VERSION ""

NS_ :

BS_:

BU_: MCPB MCPA EVCU2 AGSM

BO_ 2564502513 DIAGNOSTIC_REQUEST_FUNC_OBD: 8 EVCU2
 SG_ N_PDU : 7|64@0+ (1,0) [0|0] "" MCPB,MCPA

BO_ 156 TELEMATIC_FD_1: 32 EVCU2
 SG_ GPS_UTC_Second : 151|16@0+ (0.01,0) [0|59.99] "s"  MCPB,MCPA
 SG_ GPS_UTC_Minute : 47|8@0+ (1,0) [0|59] "min"  MCPB,MCPA
 SG_ GPS_UTC_Hour : 55|8@0+ (1,0) [0|23] "h"  MCPB,MCPA
 SG_ GPS_Date_Year : 167|16@0+ (1,0) [0|65534] "Years"  MCPB,MCPA
 SG_ GPS_Date_Month : 71|8@0+ (1,0) [1|12] "Months"  MCPB,MCPA
 SG_ GPS_Date_Day : 63|8@0+ (1,0) [1|31] "Days"  MCPB,MCPA

BO_ 1829 IPC_FD_1: 32 EVCU2
 SG_ TotalOdometer : 75|20@0+ (1,0) [0|1048575] "km"  MCPB,MCPA

BO_ 1626 IMPACT_INFO: 32 EVCU2
 SG_ IMPACTConfirm : 81|1@0+ (1,0) [0|1] "-"  MCPB,MCPA
 SG_ IMPACTCommand : 80|1@0+ (1,0) [0|1] "-"  MCPB,MCPA

BO_ 2564554482 DIAGNOSTIC_REQUEST_FD_FUNCTIONAL: 64 EVCU2
 SG_ N_PDU : 7|64@0+ (1,0) [0|0] "" MCPB,MCPA

BO_ 1155 BRAKE_FD_5: 32 EVCU2
 SG_ ESCFailSts : 83|1@0+ (1,0) [0|1] "-"  MCPB
 SG_ ABSFailSts : 87|1@0+ (1,0) [0|1] "-"  MCPB

BO_ 609 BRAKE_FD_4: 32 EVCU2
 SG_ EPBSts : 115|4@0+ (1,0) [0|14] "-"  MCPB,MCPA

BO_ 1066 BCM_FD_9: 32 EVCU2
 SG_ ExternalTemperature : 0|9@0+ (0.5,-85) [-85|170] "°C"  MCPB,MCPA

BO_ 1153 BCM_FD_10: 32 EVCU2
 SG_ CmdIgnSts : 138|3@0+ (1,0) [0|7] "" MCPB,MCPA
 SG_ MessageCounter_BCM10 : 179|4@0+ (1,0) [0|15] "-"  MCPB
 SG_ CRC_BCM10 : 191|8@0+ (1,0) [0|255] "-"  MCPB

BO_ 1032 HYBRID_THERMAL_COMMAND: 32 EVCU2
 SG_ EOPB_OIL_TEMP : 151|8@0+ (1,-50) [-50|205] "°C"  MCPB
 SG_ EOPB_OIL_FlwRate : 167|8@0+ (0.1,0) [0|25.4] "LPM"  MCPB
 SG_ EOPA_OIL_TEMP : 143|8@0+ (1,-50) [-50|205] "°C"  MCPA
 SG_ EOPA_OIL_FlwRate : 159|8@0+ (0.1,0) [0|25.4] "LPM"  MCPA

BO_ 267 HYBRID_SYSTEM_EPT1: 32 EVCU2
 SG_ WU_Timer_Value : 23|16@0+ (1,0) [0|65535] "min"  MCPB,MCPA
 SG_ PerWakeUp_Diag : 33|10@0+ (1,0) [0|1023] "-"  MCPB,MCPA

BO_ 1033 HYBRID_POWERTRAIN5: 32 EVCU2
 SG_ MessageCounter_HYBRID_POWERTRAI : 179|4@0+ (1,0) [0|15] "-"  Vector__XXX
 SG_ CRC_HYBRID_POWERTRAIN5 : 191|8@0+ (1,0) [0|255] "-"  Vector__XXX

BO_ 276 HYBRID_POWERTRAIN1: 64 EVCU2
 SG_ MessageCounter_HYBRID_POWERTRAI : 435|4@0+ (1,0) [0|15] "-"  Vector__XXX
 SG_ CRC_HYBRID_POWERTRAIN1 : 447|8@0+ (1,0) [0|255] "-"  Vector__XXX

BO_ 258 BRAKE_FD_2: 64 EVCU2
 SG_ MessageCounter_BRAKE2 : 435|4@0+ (1,0) [0|15] "-"  MCPB,MCPA
 SG_ LongAccelerationFailSts_BSM : 69|1@0+ (1,0) [0|1] "-"  MCPB,MCPA
 SG_ LongAcceleration_BSM : 35|12@0+ (0.02,-40.96) [-40.96|40.92] "m/s^2"  MCPB,MCPA
 SG_ LatAccelerationFailSts_BSM : 68|1@0+ (1,0) [0|1] "-"  MCPB,MCPA
 SG_ LatAcceleration_BSM : 19|12@0+ (0.02,-40.96) [-40.96|40.92] "m/s^2"  MCPB,MCPA
 SG_ ESCActive : 84|1@0+ (1,0) [0|1] "-"  MCPB,MCPA
 SG_ CRC_BRAKE2 : 447|8@0+ (1,0) [0|255] "-"  MCPB,MCPA
 SG_ ABSActive : 83|1@0+ (1,0) [0|1] "-"  MCPB,MCPA

BO_ 476 AGSM_FD_2: 32 AGSM
 SG_ PRNDFailSts : 82|1@0+ (1,0) [0|1] "-"  EVCU2
 SG_ PRNDdisplayFailSts : 83|1@0+ (1,0) [0|1] "-"  EVCU2
 SG_ APCM_Stat : 107|2@0+ (1,0) [0|2] "-"  EVCU2
 SG_ ShiftLeverPositionReq : 95|4@0+ (1,0) [0|15] "-"  EVCU2,MCPB
 SG_ MessageCounter_AGSM2 : 179|4@0+ (1,0) [0|15] "-"  EVCU2
 SG_ CRC_AGSM2 : 191|8@0+ (1,0) [0|255] "-"  EVCU2

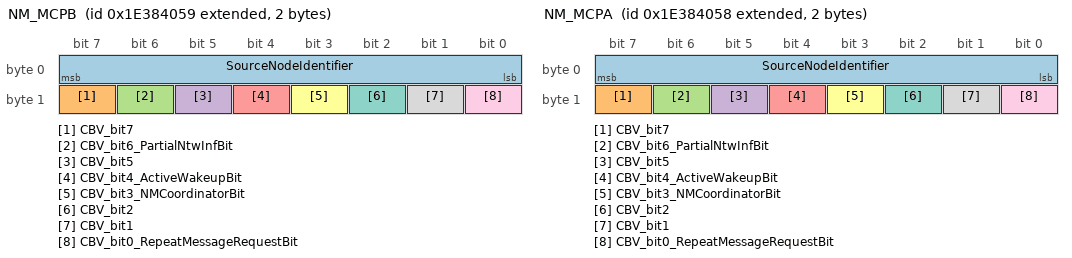
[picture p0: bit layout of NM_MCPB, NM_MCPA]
BO_ 2654486617 NM_MCPB: 2 MCPB
 SG_ SourceNodeIdentifier : 7|8@0+ (1,0) [0|255] "-"  EVCU2,MCPA,AGSM
 SG_ CBV_bit7 : 15|1@0+ (1,0) [0|1] "" EVCU2,MCPA,AGSM
 SG_ CBV_bit6_PartialNtwInfBit : 14|1@0+ (1,0) [0|1] "" EVCU2,MCPA,AGSM
 SG_ CBV_bit5 : 13|1@0+ (1,0) [0|1] "" EVCU2,MCPA,AGSM
 SG_ CBV_bit4_ActiveWakeupBit : 12|1@0+ (1,0) [0|1] "" EVCU2,MCPA,AGSM
 SG_ CBV_bit3_NMCoordinatorBit : 11|1@0+ (1,0) [0|1] "" EVCU2,MCPA,AGSM
 SG_ CBV_bit2 : 10|1@0+ (1,0) [0|1] "" EVCU2,MCPA,AGSM
 SG_ CBV_bit1 : 9|1@0+ (1,0) [0|1] "" EVCU2,MCPA,AGSM
 SG_ CBV_bit0_RepeatMessageRequestBit : 8|1@0+ (1,0) [0|1] "" EVCU2,MCPA,AGSM

BO_ 2654486616 NM_MCPA: 2 MCPA
 SG_ SourceNodeIdentifier : 7|8@0+ (1,0) [0|255] "-"  EVCU2,MCPB,AGSM
 SG_ CBV_bit7 : 15|1@0+ (1,0) [0|1] "" EVCU2,MCPB,AGSM
 SG_ CBV_bit6_PartialNtwInfBit : 14|1@0+ (1,0) [0|1] "" EVCU2,MCPB,AGSM
 SG_ CBV_bit5 : 13|1@0+ (1,0) [0|1] "" EVCU2,MCPB,AGSM
 SG_ CBV_bit4_ActiveWakeupBit : 12|1@0+ (1,0) [0|1] "" EVCU2,MCPB,AGSM
 SG_ CBV_bit3_NMCoordinatorBit : 11|1@0+ (1,0) [0|1] "" EVCU2,MCPB,AGSM
 SG_ CBV_bit2 : 10|1@0+ (1,0) [0|1] "" EVCU2,MCPB,AGSM
 SG_ CBV_bit1 : 9|1@0+ (1,0) [0|1] "" EVCU2,MCPB,AGSM
 SG_ CBV_bit0_RepeatMessageRequestBit : 8|1@0+ (1,0) [0|1] "" EVCU2,MCPB,AGSM

BO_ 496 PARK_DATA: 24 MCPB
 SG_ Plock_fdbk_sts : 7|3@0+ (1,0) [0|7] "" EVCU2
 SG_ MessageCounter_PARK_DATA : 115|4@0+ (1,0) [0|15] "" EVCU2
 SG_ CRC_PARK_DATA : 127|8@0+ (1,0) [0|255] "" EVCU2

BO_ 105 VDCM_PWT3: 64 EVCU2
 SG_ T7_Sensor_Temp : 330|11@0+ (0.1,-40) [-40|164.7] "°C"  MCPB,MCPA
 SG_ T7_CoolantTempVldty : 331|1@0+ (1,0) [0|1] "" MCPB,MCPA
 SG_ T4_Sensor_Temp : 378|11@0+ (0.1,-40) [-40|164.7] "°C"  MCPB,MCPA

BO_ 263 PT_SYSTEM_FD_1: 64 EVCU2
 SG_ GearEngagedForDisplay_PT : 12|5@0+ (1,0) [0|31] "" AGSM
 SG_ GearEngaged_PT : 132|4@0+ (1,0) [0|15] "" MCPB
 SG_ TransmissionFailSts_PT : 152|1@0+ (1,0) [0|1] "" AGSM
 SG_ ShiftLeverPosition_PT : 51|4@0+ (1,0) [0|15] "" AGSM
 SG_ MessageCounter_PT_SYSTEM_FD_1 : 435|4@0+ (1,0) [0|15] "-"  MCPB
 SG_ GearIndicationSts_PT : 153|1@0+ (1,0) [0|1] "" AGSM
 SG_ CRC_PT_SYSTEM_FD_1 : 447|8@0+ (1,0) [0|255] "-"  MCPB
 SG_ APCM_Rq_PT : 137|2@0+ (1,0) [0|3] "" AGSM

BO_ 216 PT_ENERGY_FD_1: 64 EVCU2
 SG_ BatteryVoltage_Raw_PT : 97|10@0+ (0.2,0) [0|204.60] "V"  MCPB,MCPA
 SG_ MC_PT_ENERGY_FD_1 : 435|4@0+ (1,0) [0|15] "" MCPB,MCPA
 SG_ CRC_PT_ENERGY_FD_1 : 447|8@0+ (1,0) [0|255] "" MCPB,MCPA

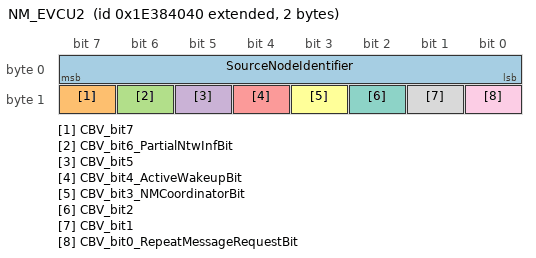
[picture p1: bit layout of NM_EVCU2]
BO_ 2654486592 NM_EVCU2: 2 EVCU2
 SG_ SourceNodeIdentifier : 7|8@0+ (1,0) [0|255] "-"  MCPB,MCPA,AGSM
 SG_ CBV_bit7 : 15|1@0+ (1,0) [0|1] "" MCPB,MCPA,AGSM
 SG_ CBV_bit6_PartialNtwInfBit : 14|1@0+ (1,0) [0|1] "" MCPB,MCPA,AGSM
 SG_ CBV_bit5 : 13|1@0+ (1,0) [0|1] "" MCPB,MCPA,AGSM
 SG_ CBV_bit4_ActiveWakeupBit : 12|1@0+ (1,0) [0|1] "" MCPB,MCPA,AGSM
 SG_ CBV_bit3_NMCoordinatorBit : 11|1@0+ (1,0) [0|1] "" MCPB,MCPA,AGSM
 SG_ CBV_bit2 : 10|1@0+ (1,0) [0|1] "" MCPB,MCPA,AGSM
 SG_ CBV_bit1 : 9|1@0+ (1,0) [0|1] "" MCPB,MCPA,AGSM
 SG_ CBV_bit0_RepeatMessageRequestBit : 8|1@0+ (1,0) [0|1] "" MCPB,MCPA,AGSM

BO_ 1811 REAL_TIME_CLOCK: 64 EVCU2
 SG_ Real_Time_Validity : 39|1@0+ (1,0) [0|1] "" MCPB,MCPA
 SG_ Real_Time_Clock : 7|32@0+ (1,0) [0|4294967295] "" MCPB,MCPA

BO_ 1065 MCPB_OBD_DTC: 32 MCPB
 SG_ MessageCounter_MCPB_OBD_DTC : 179|4@0+ (1,0) [0|15] ""  EVCU2
 SG_ MCPB_DTC_Stat2 : 26|3@0+ (1,0) [0|7] "" EVCU2
 SG_ MCPB_DTC_Stat1 : 18|3@0+ (1,0) [0|7] "" EVCU2
 SG_ MCPB_DTC_Idx2 : 31|5@0+ (1,0) [0|31] "" EVCU2
 SG_ MCPB_DTC_Idx1 : 23|5@0+ (1,0) [0|31] "" EVCU2
 SG_ MCPB_CalChar : 15|8@0+ (1,0) [0|255] "" EVCU2
 SG_ MCPB_Cal_ID_Idx : 7|6@0+ (1,0) [0|63] "" EVCU2
 SG_ CRC_MCPB_OBD_DTC : 191|8@0+ (1,0) [0|255] ""  EVCU2

BO_ 1057 MCPA_OBD_DTC: 32 MCPA
 SG_ MessageCounter_MCPA_OBD_DTC : 179|4@0+ (1,0) [0|15] ""  EVCU2
 SG_ MCPA_DTC_Stat2 : 26|3@0+ (1,0) [0|7] "" EVCU2
 SG_ MCPA_DTC_Stat1 : 18|3@0+ (1,0) [0|7] "" EVCU2
 SG_ MCPA_DTC_Idx2 : 31|5@0+ (1,0) [0|31] "" EVCU2
 SG_ MCPA_DTC_Idx1 : 23|5@0+ (1,0) [0|31] "" EVCU2
 SG_ MCPA_CalChar : 15|8@0+ (1,0) [0|255] "" EVCU2
 SG_ MCPA_Cal_ID_Idx : 7|6@0+ (1,0) [0|63] "" EVCU2
 SG_ CRC_MCPA_OBD_DTC : 191|8@0+ (1,0) [0|255] ""  EVCU2

BO_ 504 MCPB_STATUS: 32 MCPB
 SG_ MCPB_DerateReason_P : 7|4@0+ (1,0) [0|15] "-"  EVCU2
 SG_ MCPB_DC_Voltage_P : 1|10@0+ (1,0) [0|1022] "V"  EVCU2
 SG_ MCPB_DC_Volt_V_P : 3|1@0+ (1,0) [0|1] "" EVCU2
 SG_ MCPB_DC_Current_V_P : 2|1@0+ (1,0) [0|1] "" EVCU2
 SG_ MCPB_DC_Current_P : 38|15@0+ (0.1,-1638.4) [-1638.4|1638.3] "A"  EVCU2
 SG_ MCPB_CoolantTemp_P : 18|11@0+ (0.1,-40) [-40|164.7] "°C"  EVCU2
 SG_ MC_MCPB_STATUS : 179|4@0+ (1,0) [0|15] "-"  EVCU2
 SG_ CRC_MCPB_STATUS : 191|8@0+ (1,0) [0|255] "-"  EVCU2
 SG_ MCPB_Inverter_Temp_P : 71|8@0+ (1,-40) [-40|215] "°C"  EVCU2
 SG_ MCPB_PIM_DC_Side_Busbar_Temp_P : 79|8@0+ (1,-40) [-40|215] "°C"  EVCU2
 SG_ MCPB_Rotor_Temperature_P : 55|8@0+ (1,-40) [-40|215] "ºC"  EVCU2
 SG_ MCPB_Service_Lamp_Request_P : 19|1@0+ (1,0) [0|1] "" EVCU2
 SG_ CLrDiagInfo_MCPB_P : 39|1@0+ (1,0) [0|1] "" EVCU2
 SG_ MCPB_Control_Board_Temperature_P : 63|8@0+ (1,-40) [-40|215] "" EVCU2

BO_ 503 MCPA_STATUS: 32 MCPA
 SG_ MCPA_DerateReason_P : 7|4@0+ (1,0) [0|15] "" EVCU2
 SG_ MCPA_DC_Voltage_P : 1|10@0+ (1,0) [0|1023] "V"  EVCU2
 SG_ MCPA_DC_Volt_V_P : 3|1@0+ (1,0) [0|1] "" EVCU2
 SG_ MCPA_DC_Current_V_P : 2|1@0+ (1,0) [0|1] "" EVCU2
 SG_ MCPA_DC_Current_P : 38|15@0+ (0.1,-1638.4) [-1638.4|1638.3] "A"  EVCU2
 SG_ MCPA_CoolantTemp_P : 18|11@0+ (0.1,-40) [-40|164.7] "C"  EVCU2
 SG_ MC_MCPA_STATUS : 179|4@0+ (1,0) [0|15] "-"  EVCU2
 SG_ CRC_MCPA_STATUS : 191|8@0+ (1,0) [0|255] "-"  EVCU2
 SG_ MCPA_Inverter_Temp_P : 71|8@0+ (1,-40) [-40|215] "ºC"  EVCU2
 SG_ MCPA_PIM_DC_Side_Busbar_Temp_P : 79|8@0+ (1,-40) [-40|215] "ºC"  EVCU2
 SG_ MCPA_Rotor_Temperature_P : 55|8@0+ (1,-40) [-40|215] "ºC"  EVCU2
 SG_ MCPA_Service_Lamp_Request_P : 19|1@0+ (1,0) [0|1] "" EVCU2
 SG_ CLrDiagInfo_MCPA_P : 39|1@0+ (1,0) [0|1] "" EVCU2
 SG_ MCPA_Control_Board_Temperature_P : 63|8@0+ (1,-40) [-40|215] "ºC"  EVCU2

BO_ 297 INVTARGET_PROPULSION2: 48 EVCU2
 SG_ UDCMin_Unlim_MCPB_P : 111|16@0+ (0.01,0) [0|655.35] "V"  MCPB
 SG_ UDCMin_Unlim_MCPA_P : 23|16@0+ (0.01,0) [0|655.35] "V"  MCPA
 SG_ UDCMax_Unlim_MCPB_P : 143|16@0+ (0.01,0) [0|655.35] "V"  MCPB
 SG_ UDCMax_Unlim_MCPA_P : 39|16@0+ (0.01,0) [0|655.35] "V"  MCPA
 SG_ TqGrdtLim_MCPB_P : 79|16@0+ (0.1,0) [0|6553.5] "Nm/s"  MCPB
 SG_ TqGrdtLim_MCPA_P : 7|16@0+ (0.1,0) [0|6553.5] "Nm/s"  MCPA
 SG_ SpdGrdtLim_MCPB_P : 277|11@0+ (20,0) [0|40940] "rpm/s"  MCPB
 SG_ SpdGrdtLim_MCPA_P : 282|11@0+ (20,0) [0|40940] "rpm/s"  MCPA
 SG_ Pwr_Electr_Loop_FlwRate_MCPB_P : 63|8@0+ (0.1,0) [0|25.5] "LPM"  MCPB
 SG_ Pwr_Electr_Loop_FlwRate_MCPA_P : 55|8@0+ (0.1,0) [0|25.5] "LPM"  MCPA
 SG_ MC_INVTARGET_PROPULSION2 : 307|4@0+ (1,0) [0|15] "-"  MCPB,MCPA
 SG_ EVCU_MotorB_Speed : 191|16@0+ (1,-32768) [-32768|32767] "rpm"  MCPB
 SG_ EVCU_MotorA_Speed : 175|16@0+ (1,-32768) [-32768|32767] "rpm"  MCPA
 SG_ CRC_INVTARGET_PROPULSION2 : 319|8@0+ (1,0) [0|255] "-"  MCPB,MCPA

BO_ 296 INVTARGET_PROPULSION1: 48 EVCU2
 SG_ VehicleSpeedVSOSig_P : 55|13@0+ (0.0625,0) [0|511.875] "Km/h"  MCPB,MCPA
 SG_ TorqueCommand_MCPB_P : 157|14@0+ (0.125,-1023) [-1023|1024.875] "Nm"  MCPB
 SG_ TorqueCommand_MCPA_P : 139|14@0+ (0.125,-1023) [-1023|1024.875] "Nm"  MCPA
 SG_ TargetMotorRPM_MCPB_P : 23|16@0+ (0.5,-16384) [-16384|16383.5] "rpm"  MCPB
 SG_ TargetMotorRPM_MCPA_P : 7|16@0+ (0.5,-16384) [-16384|16383.5] "rpm"  MCPA
 SG_ ShiftLeverPosition_P : 273|4@0+ (1,0) [0|15] "" MCPB
 SG_ ParkCmd_PT_P : 259|2@0+ (1,0) [0|3] "" MCPB
 SG_ Mtr_6SO_Request_MCPB_P : 248|1@0+ (1,0) [0|1] "" MCPB
 SG_ Mtr_6SO_Request_MCPA_P : 249|1@0+ (1,0) [0|1] "" MCPA
 SG_ ModeCommand_MCPB_P : 227|4@0+ (1,0) [0|15] "" MCPB
 SG_ ModeCommand_MCPA_P : 231|4@0+ (1,0) [0|15] "" MCPA
 SG_ MC_INVTARGET_PROPULSION1 : 307|4@0+ (1,0) [0|15] "" MCPB,MCPA
 SG_ CRC_INVTARGET_PROPULSION1 : 319|8@0+ (1,0) [0|255] "-"  MCPB,MCPA
 SG_ CmdIgnSts_P : 58|3@0+ (1,0) [0|7] "" MCPB,MCPA
 SG_ BPCM_HV_TractionBusVoltage_P : 271|11@0+ (1,0) [0|2047] "V"  MCPB,MCPA
 SG_ BPCM_HV_Trac_Main_Contac_Sts_P : 276|3@0+ (1,0) [0|7] "" MCPB,MCPA
 SG_ AEMD_MinOffset_MCPB_P : 195|14@0+ (0.125,-1023) [-1023|1024.875] "Nm"  MCPB
 SG_ AEMD_MinOffset_MCPA_P : 119|14@0+ (0.125,-1023) [-1023|1024.875] "Nm"  MCPA
 SG_ AEMD_MaxOffset_MCPB_P : 213|14@0+ (0.125,-1023) [-1023|1024.875] "Nm"  MCPB
 SG_ AEMD_MaxOffset_MCPA_P : 121|14@0+ (0.125,-1023) [-1023|1024.875] "Nm"  MCPA
 SG_ AEMD_Cutoff_FreqLow_MCPB_P : 87|8@0+ (0.1,4.5) [4.5|30] "Hz"  MCPB
 SG_ AEMD_Cutoff_FreqLow_MCPA_P : 71|8@0+ (0.1,4.5) [4.5|30] "Hz"  MCPA
 SG_ AEMD_Cutoff_FreqHigh_MCPB_P : 95|8@0+ (0.1,0) [0|25.5] "Hz"  MCPB
 SG_ AEMD_Cutoff_FreqHigh_MCPA_P : 79|8@0+ (0.1,0) [0|25.5] "Hz"  MCPA
 SG_ AEMD_Sclr_Gn_MCPB_P : 242|9@0+ (0.02,0) [0|10.22] "rad/s/Nm"  MCPB
 SG_ AEMD_Sclr_Gn_MCPA_P : 235|9@0+ (0.02,0) [0|10.22] "rad/s/Nm"  MCPA

BO_ 124 GLIWA_MCPB_TX: 8 MCPB
 SG_ N_PDU : 7|64@0+ (1,0) [0|0] "" EVCU2

BO_ 127 GLIWA_MCPB_RX: 8 EVCU2
 SG_ N_PDU : 7|64@0+ (1,0) [0|0] "" MCPB

BO_ 123 GLIWA_MCPA_TX: 8 MCPA
 SG_ N_PDU : 7|64@0+ (1,0) [0|0] "" EVCU2

BO_ 126 GLIWA_MCPA_RX: 8 EVCU2
 SG_ N_PDU : 7|64@0+ (1,0) [0|0] "" MCPA

BO_ 294 MCPB_PROPULSION: 64 MCPB
 SG_ PlockFailSts_P : 179|3@0+ (1,0) [0|6] "" EVCU2
 SG_ Plock_PosSensor_P : 196|3@0+ (1,0) [0|6] "" EVCU2
 SG_ Plock_MotorPosSts_P : 188|3@0+ (1,0) [0|6] "" EVCU2
 SG_ Plock_fdbk_sts_P : 191|3@0+ (1,0) [0|7] "" EVCU2
 SG_ MPR_PosSensor_P : 199|3@0+ (1,0) [0|6] "" EVCU2
 SG_ MCPB_Torque_Achieved_V_P : 54|1@0+ (1,0) [0|1] "" EVCU2
 SG_ MCPB_Torque_Achieved_P : 21|14@0+ (0.125,-1023) [-1023|1024.875] "Nm"  EVCU2
 SG_ MCPB_TorqAchieved_AEMD_V_P : 71|1@0+ (1,0) [0|1] "" EVCU2
 SG_ MCPB_TorqAchieved_AEMD_P : 85|14@0+ (0.125,-1023) [-1023|1024.875] "Nm"  EVCU2
 SG_ MCPB_SPT_Stat_P : 39|2@0+ (1,0) [0|3] "" EVCU2
 SG_ MCPB_Spd_Lim_P : 135|16@0+ (1,-32767) [-32767|32678] "rpm"  EVCU2
 SG_ MCPB_RPM_V_P : 70|1@0+ (1,0) [0|1] "" EVCU2
 SG_ MCPB_RPM_P : 7|16@0+ (1,-32768) [-32768|32767] "rpm"  EVCU2
 SG_ MCPB_MtrMinCpbltyTrq_P : 117|14@0+ (0.125,-1023) [-1023|1024.875] "Nm"  EVCU2
 SG_ MCPB_MtrMaxCpbltyTrq_P : 101|14@0+ (0.125,-1023) [-1023|1024.875] "Nm"  EVCU2
 SG_ MCPB_MtrIndex_P : 44|5@0+ (1,0) [0|31] "" EVCU2
 SG_ MCPB_MinTorq_P : 69|14@0+ (0.125,-1023) [-1023|1024.875] "Nm"  EVCU2
 SG_ MCPB_MaxTorq_P : 53|14@0+ (0.125,-1023) [-1023|1024.875] "Nm"  EVCU2
 SG_ MCPB_Invrtr_State_P : 183|4@0+ (1,0) [0|15] "" EVCU2
 SG_ MCPB_InterlockSts_P : 103|2@0+ (1,0) [0|3] "" EVCU2
 SG_ MCPB_HV_CnctrOpn_Req_P : 119|1@0+ (1,0) [0|1] "" EVCU2
 SG_ MCPB_Dschrge_Status_P : 87|2@0+ (1,0) [0|3] "" EVCU2
 SG_ MCPB_DeratingFactor_P : 37|6@0+ (0.02,0) [0|1.26] "" EVCU2
 SG_ MCPB_CpbltySpdDivVolt_P : 167|16@0+ (1,0) [0|65535] "V"  EVCU2
 SG_ MCPB_AccelRawV_P : 55|1@0+ (1,0) [0|1] "" EVCU2
 SG_ MCPB_6SO_Status_P : 23|2@0+ (1,0) [0|3] "" EVCU2
 SG_ MCPB_3PS_Pos_P : 118|1@0+ (1,0) [0|1] "" EVCU2
 SG_ MCPB_AccelRaw_P : 151|16@0+ (1,-32768) [-32768|32767] "RPM/s"  EVCU2
 SG_ MC_MCPB_PROPULSION : 435|4@0+ (1,0) [0|15] "-"  EVCU2
 SG_ CRC_MCPB_PROPULSION : 447|8@0+ (1,0) [0|255] "-"  EVCU2
 SG_ MCPB_AC_Isolation_Status_P : 193|2@0+ (1,0) [0|3] "" EVCU2
 SG_ MCPB_Temp_P : 207|8@0+ (1,-40) [-40|215] "ºC"  EVCU2

BO_ 293 MCPA_PROPULSION: 64 MCPA
 SG_ MCPA_Torque_Achieved_V_P : 54|1@0+ (1,0) [0|1] "" EVCU2
 SG_ MCPA_Torque_Achieved_P : 21|14@0+ (0.125,-1023) [-1023|1024.875] "Nm"  EVCU2
 SG_ MCPA_TorqAchieved_AEMD_V_P : 71|1@0+ (1,0) [0|1] "" EVCU2
 SG_ MCPA_TorqAchieved_AEMD_P : 85|14@0+ (0.125,-1023) [-1023|1024.875] "Nm"  EVCU2
 SG_ MCPA_SPT_Stat_P : 39|2@0+ (1,0) [0|3] "" EVCU2
 SG_ MCPA_Spd_Lim_P : 135|16@0+ (1,-32767) [-32767|32768] "rpm"  EVCU2
 SG_ MCPA_RPM_V_P : 70|1@0+ (1,0) [0|1] "" EVCU2
 SG_ MCPA_RPM_P : 7|16@0+ (1,-32768) [-32768|32767] "rpm"  EVCU2
 SG_ MCPA_MtrMinCpbltyTrq_P : 117|14@0+ (0.125,-1023) [-1023|1024.875] "Nm"  EVCU2
 SG_ MCPA_MtrMaxCpbltyTrq_P : 101|14@0+ (0.125,-1023) [-1023|1024.875] "Nm"  EVCU2
 SG_ MCPA_MtrIndex_P : 44|5@0+ (1,0) [0|31] "" EVCU2
 SG_ MCPA_MinTorq_P : 69|14@0+ (0.125,-1023) [-1023|1024.875] "Nm"  EVCU2
 SG_ MCPA_MaxTorq_P : 53|14@0+ (0.125,-1023) [-1023|1024.875] "Nm"  EVCU2
 SG_ MCPA_Invrtr_State_P : 183|4@0+ (1,0) [0|15] "" EVCU2
 SG_ MCPA_InterlockSts_P : 103|2@0+ (1,0) [0|3] "" EVCU2
 SG_ MCPA_HV_CnctrOpn_Req_P : 119|1@0+ (1,0) [0|1] "" EVCU2
 SG_ MCPA_Dschrge_Status_P : 87|2@0+ (1,0) [0|3] "" EVCU2
 SG_ MCPA_DeratingFactor_P : 37|6@0+ (0.02,0) [0|1.26] "" EVCU2
 SG_ MCPA_CpbltySpdDivVolt_P : 167|16@0+ (1,0) [0|65535] "rpm"  EVCU2
 SG_ MCPA_AccelRawV_P : 55|1@0+ (1,0) [0|1] "" EVCU2
 SG_ MCPA_6SO_Status_P : 23|2@0+ (1,0) [0|3] "" EVCU2
 SG_ MCPA_3PS_Pos_P : 118|1@0+ (1,0) [0|1] "" EVCU2
 SG_ MCPA_AccelRaw_P : 151|16@0+ (1,-32768) [-32768|32767] "RPM/s"  EVCU2
 SG_ MC_MCPA_PROPULSION : 435|4@0+ (1,0) [0|15] "-"  EVCU2
 SG_ CRC_MCPA_PROPULSION : 447|8@0+ (1,0) [0|255] "-"  EVCU2
 SG_ MCPA_Temp_P : 207|8@0+ (1,-40) [-40|215] "°C"  EVCU2
 SG_ MCPA_AC_Isolation_Status_P : 199|2@0+ (1,0) [0|3] "" EVCU2

CM_ "Project_KM_ProjectStandard_FD-CAN16 [CS00155_FD]";
CM_ SG_ 2564502513 N_PDU "This signal is used for diagnostic purposes";
CM_ SG_ 156 GPS_UTC_Second "GPS UTC second";
CM_ SG_ 156 GPS_UTC_Minute "GPS UTC minute";
CM_ SG_ 156 GPS_UTC_Hour "GPS UTC hour";
CM_ SG_ 156 GPS_Date_Year "GPS date year";
CM_ SG_ 156 GPS_Date_Month "GPS date month";
CM_ SG_ 156 GPS_Date_Day "GPS date day";
CM_ SG_ 1829 TotalOdometer "Used to give information about the total odometer value in km.";
CM_ SG_ 1626 IMPACTConfirm "This signal is used to confirm that a crash happened";
CM_ SG_ 1626 IMPACTCommand "This signal is used to indicate that a crash happened";
CM_ SG_ 2564554482 N_PDU "This signal is used for diagnostic purposes";
CM_ SG_ 1155 ESCFailSts "0";
CM_ SG_ 1155 ABSFailSts "0";
CM_ SG_ 609 EPBSts "0";
CM_ SG_ 1153 MessageCounter_BCM10 "This signal is a counter used for safety checks strategies. This counter is incremented of 1 (one) unit at each frame transmission.";
CM_ SG_ 1153 CRC_BCM10 "CRC according to SAE J1850 standard at each frame transmission.";
CM_ SG_ 1153 CmdIgnSts "Used to give information about the key selector position";
CM_ SG_ 1032 EOPB_OIL_TEMP "EOPB Oil Temperature in EDM B";
CM_ SG_ 1032 EOPB_OIL_FlwRate "EOPB Oil Flow Rate through EDM B";
CM_ SG_ 1032 EOPA_OIL_TEMP "EOPA Oil Temperature in EDM A";
CM_ SG_ 1032 EOPA_OIL_FlwRate "EOPA Oil Flow Rate through EDM A";
CM_ SG_ 267 PerWakeUp_Diag "Periodic wakeup diagnostics";
CM_ SG_ 267 WU_Timer_Value "HCP wake-up timer value";
CM_ SG_ 1033 MessageCounter_HYBRID_POWERTRAI "This signal is a counter used for safety checks strategies. This counter is incremented of 1 (one) unit at each frame transmission.";
CM_ SG_ 1033 CRC_HYBRID_POWERTRAIN5 "CRC according to SAE J1850 standard at each frame transmission.";
CM_ SG_ 276 MessageCounter_HYBRID_POWERTRAI "This signal is a counter used for safety checks strategies. This counter is incremented of 1 (one) unit at each frame transmission.";
CM_ SG_ 276 CRC_HYBRID_POWERTRAIN1 "CRC according to SAE J1850 standard at each frame transmission.";
CM_ SG_ 258 MessageCounter_BRAKE2 "This signal is a counter used for safety checks strategies. This counter is incremented of 1 (one) unit at each frame transmission.";
CM_ SG_ 258 LongAccelerationFailSts_BSM "This signal indicates the status of Longitudinal acceleration signal";
CM_ SG_ 258 LongAcceleration_BSM "This signal indicates the Longitudinal Acceleration Value";
CM_ SG_ 258 LatAccelerationFailSts_BSM "This signal indicates the status of Lateral Acceleration Signal";
CM_ SG_ 258 LatAcceleration_BSM "This signal indicates the Lateral Acceleration Value";
CM_ SG_ 258 ESCActive "This signal is set to Active when the brake intervention by ESC is active.";
CM_ SG_ 258 CRC_BRAKE2 "CRC according to SAE J1850 standard at each frame transmission.";
CM_ SG_ 258 ABSActive "This signal is set to Active when the ABS functionality is active.";
CM_ SG_ 476 ShiftLeverPositionReq "This signal describes the shift lever position requested by the driver.";
CM_ SG_ 476 PRNDFailSts "-";
CM_ SG_ 476 PRNDdisplayFailSts "-";
CM_ SG_ 476 APCM_Stat "Auto position correction mode status";
CM_ SG_ 476 CRC_AGSM2 "CRC according to SAE J1850 standard at each frame transmission.";
CM_ SG_ 476 MessageCounter_AGSM2 "This signal is a counter used for safety checks strategies. This counter is incremented of 1 (one) unit at each frame transmission.";
CM_ SG_ 2654486617 SourceNodeIdentifier "Source Node Identifier";
CM_ SG_ 2654486617 CBV_bit6_PartialNtwInfBit "Partial Network Information Bit (PNI)";
CM_ SG_ 2654486617 CBV_bit4_ActiveWakeupBit "Active Wakeup Bit";
CM_ SG_ 2654486617 CBV_bit3_NMCoordinatorBit "NM Coordinator Sleep Bit";
CM_ SG_ 2654486617 CBV_bit0_RepeatMessageRequestBit "Repeat Message Request Bit";
CM_ SG_ 2654486616 SourceNodeIdentifier "Source Node Identifier";
CM_ SG_ 2654486616 CBV_bit6_PartialNtwInfBit "Partial Network Information Bit (PNI)";
CM_ SG_ 2654486616 CBV_bit4_ActiveWakeupBit "Active Wakeup Bit";
CM_ SG_ 2654486616 CBV_bit3_NMCoordinatorBit "NM Coordinator Sleep Bit";
CM_ SG_ 2654486616 CBV_bit0_RepeatMessageRequestBit "Repeat Message Request Bit";
CM_ SG_ 496 Plock_fdbk_sts "Park lock status";
CM_ SG_ 496 CRC_PARK_DATA "CRC according to SAE J1850 standard at each frame transmission.";
CM_ SG_ 496 MessageCounter_PARK_DATA "This signal is a counter used for safety checks strategies. This counter is incremented of 1 (one) unit at each frame transmission.";
CM_ SG_ 105 T7_Sensor_Temp "T7 Temperature sensor";
CM_ SG_ 105 T7_CoolantTempVldty "Inlet inverter temperature validity";
CM_ SG_ 105 T4_Sensor_Temp "T4 Temperature sensor";
CM_ SG_ 263 TransmissionFailSts_PT "Transmission Failure Status";
CM_ SG_ 263 ShiftLeverPosition_PT "Shift Lever Position";
CM_ SG_ 263 MessageCounter_PT_SYSTEM_FD_1 "This signal is a counter used for safety checks strategies. This counter is incremented of 1 (one) unit at each frame transmission.";
CM_ SG_ 263 GearIndicationSts_PT "Gear Indication Status";
CM_ SG_ 263 GearEngagedForDisplay_PT "Transmission Gear Engaged signal for the instrument cluster display";
CM_ SG_ 263 GearEngaged_PT "Current engaged gear";
CM_ SG_ 263 CRC_PT_SYSTEM_FD_1 "CRC according to SAE J1850 standard at each frame transmission.";
CM_ SG_ 263 APCM_Rq_PT "Auto position correction mode request";
CM_ SG_ 216 BatteryVoltage_Raw_PT "Battery Voltage value measured from the electrified powertrain control module pin";
CM_ SG_ 216 CRC_PT_ENERGY_FD_1 "CRC according to SAE J1850 standard at each frame transmission.";
CM_ SG_ 216 MC_PT_ENERGY_FD_1 "This signal is a counter used for safety checks strategies. This counter is incremented of 1 (one) unit at each frame transmission.";
CM_ SG_ 1811 Real_Time_Validity "EVCU Real Time Clock Validity";
CM_ SG_ 1811 Real_Time_Clock "EVCU Real Time Clock";
CM_ SG_ 1065 CRC_MCPB_OBD_DTC "CRC according to SAE J1850 standard at each frame transmission.";
CM_ SG_ 1065 MessageCounter_MCPB_OBD_DTC "This signal is a counter used for safety checks strategies. This counter is incremented of 1 (one) unit at each frame transmission.";
CM_ SG_ 1065 MCPB_DTC_Stat2 "MCPB diagnostic trouble code status 1";
CM_ SG_ 1065 MCPB_DTC_Stat1 "MCPB diagnostic trouble code status 1";
CM_ SG_ 1065 MCPB_DTC_Idx2 "MCPB diagnostic trouble code index 2";
CM_ SG_ 1065 MCPB_DTC_Idx1 "MCPB diagnostic trouble code index 1";
CM_ SG_ 1065 MCPB_CalChar "MCPB Calibration CVN";
CM_ SG_ 1065 MCPB_Cal_ID_Idx "MCPB Calibration ID Index";
CM_ SG_ 1057 MessageCounter_MCPA_OBD_DTC "This signal is a counter used for safety checks strategies. This counter is incremented of 1 (one) unit at each frame transmission.";
CM_ SG_ 1057 MCPA_DTC_Stat2 "MCPA diagnostic trouble code status 1";
CM_ SG_ 1057 MCPA_DTC_Stat1 "MCPA diagnostic trouble code status 1";
CM_ SG_ 1057 MCPA_DTC_Idx2 "MCPA diagnostic trouble code index 2";
CM_ SG_ 1057 MCPA_DTC_Idx1 "MCPA diagnostic trouble code index 1";
CM_ SG_ 1057 MCPA_CalChar "MCPA Calibration CVN";
CM_ SG_ 1057 MCPA_Cal_ID_Idx "MCPA Calibration ID Index";
CM_ SG_ 1057 CRC_MCPA_OBD_DTC "CRC according to SAE J1850 standard at each frame transmission.";
CM_ SG_ 504 MCPB_Rotor_Temperature_P "Rotor Temperature from Motor";
CM_ SG_ 504 MCPB_PIM_DC_Side_Busbar_Temp_P "MCPB busbar temperature in DC side";
CM_ SG_ 504 MCPB_Inverter_Temp_P "Motor Inverter Temperature";
CM_ SG_ 504 MCPB_DerateReason_P "Inverter Derating Reason.";
CM_ SG_ 504 MCPB_Service_Lamp_Request_P "The Service Light Request from the MCPB";
CM_ SG_ 504 MCPB_DC_Voltage_P "This signal indicates the Inverter Rear Right DC Voltage.";
CM_ SG_ 504 MCPB_DC_Volt_V_P "Achieved Torque value Validity, [1] = True";
CM_ SG_ 504 MCPB_DC_Current_V_P "Achieved Torque value Validity, [1] = True";
CM_ SG_ 504 MCPB_DC_Current_P "Motor B DC Current";
CM_ SG_ 504 MCPB_CoolantTemp_P "PIM Coolant Temperature";
CM_ SG_ 504 MCPB_Control_Board_Temperature_P "Motor Control Board temperature";
CM_ SG_ 504 MC_MCPB_STATUS "Message counter according to SAE J1850 standard that has to be calculated from bit 63 to bit 8 at each frame transmission.";
CM_ SG_ 504 CRC_MCPB_STATUS "CRC according to SAE J1850 standard that has to be calculated from bit 63 to bit 8 at each frame transmission.";
CM_ SG_ 504 CLrDiagInfo_MCPB_P "Legislative Diagnostic Clear information for MCPB";
CM_ SG_ 503 MCPA_Service_Lamp_Request_P "The Service Light Request from the MCPA";
CM_ SG_ 503 MCPA_Rotor_Temperature_P "Rotor Temperature from Motor";
CM_ SG_ 503 MCPA_PIM_DC_Side_Busbar_Temp_P "MCPA busbar temperature in DC side";
CM_ SG_ 503 MCPA_Inverter_Temp_P "Motor Inverter Temperature";
CM_ SG_ 503 MCPA_DerateReason_P "Inverter Derating Reason";
CM_ SG_ 503 MCPA_DC_Voltage_P "Inverter Front DC Voltage.";
CM_ SG_ 503 MCPA_DC_Volt_V_P "Motor A DC current validity, [1] = True";
CM_ SG_ 503 MCPA_DC_Current_V_P "Motor A DC current validity, [1] = True";
CM_ SG_ 503 MCPA_DC_Current_P "Motor A DC Current";
CM_ SG_ 503 MCPA_CoolantTemp_P "PIM Coolant Temperature";
CM_ SG_ 503 MCPA_Control_Board_Temperature_P "Motor Control Board temperature";
CM_ SG_ 503 MC_MCPA_STATUS "Message counter according to SAE J1850 standard that has to be calculated from bit 63 to bit 8 at each frame transmission.";
CM_ SG_ 503 CRC_MCPA_STATUS "CRC according to SAE J1850 standard that has to be calculated from bit 63 to bit 8 at each frame transmission.";
CM_ SG_ 503 CLrDiagInfo_MCPA_P "Legislative Diagnostic Clear information for MCPA";
CM_ SG_ 297 UDCMin_Unlim_MCPB_P "Minimum DC voltage limit before linear generator derating Consider Max or Min torque. Default 36V";
CM_ SG_ 297 UDCMin_Unlim_MCPA_P "Minimum DC voltage limit before linear generator derating Consider Max or Min torque. Default 36V";
CM_ SG_ 297 UDCMax_Unlim_MCPB_P "Maximum DC voltage limit before linear generator derating Consider Max or Min torque. Default 52V";
CM_ SG_ 297 UDCMax_Unlim_MCPA_P "Maximum DC voltage limit before linear generator derating Consider Max or Min torque. Default 52V";
CM_ SG_ 297 TqGrdtLim_MCPB_P "Positive or Negative Torque Gradient applied for Torque Control Mode and Speed Control Mode. Default 1000Nm/s";
CM_ SG_ 297 SpdGrdtLim_MCPB_P "Positive or negative (symetric) Speed Request Gradient applicable on both sign only for Speed Control Mode. Default 25,000 rpm/s";
CM_ SG_ 297 TqGrdtLim_MCPA_P "Positive or Negative Torque Gradient applied for Torque Control Mode and Speed Control Mode. Default 1000Nm/s";
CM_ SG_ 297 SpdGrdtLim_MCPA_P "Positive or negative (symetric) Speed Request Gradient applicable on both sign only for Speed Control Mode. Default 25,000 rpm/s";
CM_ SG_ 297 Pwr_Electr_Loop_FlwRate_MCPB_P "Inverter cooling liquid flow rate information";
CM_ SG_ 297 Pwr_Electr_Loop_FlwRate_MCPA_P "Inverter cooling liquid flow rate information";
CM_ SG_ 297 MC_INVTARGET_PROPULSION2 "Message counter according to SAE J1850 standard that has to be calculated from bit 63 to bit 8 at each frame transmission.";
CM_ SG_ 297 EVCU_MotorB_Speed "Motor B Speed Calculted by Supervisory Controller";
CM_ SG_ 297 EVCU_MotorA_Speed "Motor A Speed Calculted by Supervisory Controller";
CM_ SG_ 297 CRC_INVTARGET_PROPULSION2 "CRC according to SAE J1850 standard that has to be calculated from bit 63 to bit 8 at each frame transmission.";
CM_ SG_ 296 VehicleSpeedVSOSig_P "It is the average vehicle speed calculated.";
CM_ SG_ 296 TorqueCommand_MCPB_P "Torque command for MCPB";
CM_ SG_ 296 TorqueCommand_MCPA_P "Torque command for MCPA";
CM_ SG_ 296 TargetMotorRPM_MCPB_P "Target Motor RPM for MCPB";
CM_ SG_ 296 TargetMotorRPM_MCPA_P "Target Motor RPM for MCPA";
CM_ SG_ 296 ShiftLeverPosition_P "Shift Lever Position";
CM_ SG_ 296 ParkCmd_PT_P "Park Command for MCP.";
CM_ SG_ 296 Mtr_6SO_Request_MCPB_P "Six Switch Open Request  for MCPB (1=RequestActive; 0=RequestNotActive)";
CM_ SG_ 296 Mtr_6SO_Request_MCPA_P "Six Switch Open Request  for MCPA (1=RequestActive; 0=RequestNotActive)";
CM_ SG_ 296 ModeCommand_MCPB_P "Mode command for MCPB";
CM_ SG_ 296 ModeCommand_MCPA_P "Mode command for MCPA";
CM_ SG_ 296 CRC_INVTARGET_PROPULSION1 "CRC according to SAE J1850 standard that has to be calculated from bit 63 to bit 8 at each frame transmission.";
CM_ SG_ 296 CmdIgnSts_P "Used to give information about the key selector position";
CM_ SG_ 296 BPCM_HV_TractionBusVoltage_P "Battery link traction bus voltage.";
CM_ SG_ 296 BPCM_HV_Trac_Main_Contac_Sts_P "Traction main contactor physical relay status";
CM_ SG_ 296 AEMD_Sclr_Gn_MCPB_P "MCPB AEMD Scalar Gain";
CM_ SG_ 296 AEMD_Sclr_Gn_MCPA_P "MCPA AEMD Scalar Gain";
CM_ SG_ 296 AEMD_MinOffset_MCPB_P "MCPB AEMD Min Offset";
CM_ SG_ 296 AEMD_MinOffset_MCPA_P "MCPA AEMD Min Offset";
CM_ SG_ 296 AEMD_MaxOffset_MCPB_P "MCPB AEMD Max Offset";
CM_ SG_ 296 AEMD_MaxOffset_MCPA_P "MCPA AEMD Max Offset";
CM_ SG_ 296 AEMD_Cutoff_FreqLow_MCPB_P "AEMD cut-off Frequency Low for MCPB";
CM_ SG_ 296 AEMD_Cutoff_FreqLow_MCPA_P "AEMD cut-off Frequency Low for MCPA";
CM_ SG_ 296 AEMD_Cutoff_FreqHigh_MCPB_P "AEMD cut-off Frequency High for MCPB";
CM_ SG_ 296 AEMD_Cutoff_FreqHigh_MCPA_P "AEMD cut-off Frequency High for MCPA";
CM_ SG_ 294 PlockFailSts_P "Park Lock Fail Sts";
CM_ SG_ 294 Plock_PosSensor_P "Par lock physical position sensor feedback";
CM_ SG_ 294 Plock_MotorPosSts_P "Park lock motor position status";
CM_ SG_ 294 Plock_fdbk_sts_P "Park lock status";
CM_ SG_ 294 MPR_PosSensor_P "Manual Park Release sensor feedback";
CM_ SG_ 294 MCPB_Torque_Achieved_V_P "Achieved Torque value Validity, [1] = True";
CM_ SG_ 294 MCPB_Torque_Achieved_P "Motr B Torque Achieved";
CM_ SG_ 294 MCPB_TorqAchieved_AEMD_V_P "Motor Torque Achieved Validity";
CM_ SG_ 294 MCPB_TorqAchieved_AEMD_P "Motor Torque Achieved";
CM_ SG_ 294 MCPB_Temp_P "Motor Stator Temperature";
CM_ SG_ 294 MCPB_SPT_Stat_P "Inverter Isolation Status";
CM_ SG_ 294 MCPB_Spd_Lim_P "Limited motor speed during reduced performance from MCP B";
CM_ SG_ 294 MCPB_RPM_V_P "Motor B Speed Validity, [1] = True";
CM_ SG_ 294 MCPB_RPM_P "Motor B Speed Raw";
CM_ SG_ 294 MCPB_MtrMinCpbltyTrq_P "Motor B Min Capability Torque";
CM_ SG_ 294 MCPB_MtrMaxCpbltyTrq_P "Motor B Max Capability Torque";
CM_ SG_ 294 MCPB_MtrIndex_P "Motor B Capability Curve Array Index";
CM_ SG_ 294 MCPB_MinTorq_P "Motor B Minimum Torque";
CM_ SG_ 294 MCPB_MaxTorq_P "Motor B Maximum Torque";
CM_ SG_ 294 MCPB_Invrtr_State_P "Inverter State of Operation of Motor B";
CM_ SG_ 294 MCPB_InterlockSts_P "Rear right inverter interlock state";
CM_ SG_ 294 MCPB_HV_CnctrOpn_Req_P "HV Battery pack contactor request";
CM_ SG_ 294 MCPB_Dschrge_Status_P "The active discharge status of MCPB";
CM_ SG_ 294 MCPB_DeratingFactor_P "Motor B Derating Factor";
CM_ SG_ 294 MCPB_CpbltySpdDivVolt_P "Motor B Speed at Capability Curve";
CM_ SG_ 294 MCPB_AccelRawV_P "Motor B Acceleration Validity";
CM_ SG_ 294 MCPB_AccelRaw_P "Motor B Acceleration";
CM_ SG_ 294 MCPB_AC_Isolation_Status_P "Motor AC Isolation Status";
CM_ SG_ 294 MCPB_6SO_Status_P "Motor B 6SO Status";
CM_ SG_ 294 MCPB_3PS_Pos_P "3 phase motor short possible from MCP B; True = [1]";
CM_ SG_ 294 MC_MCPB_PROPULSION "Message counter according to SAE J1850 standard that has to be calculated from bit 63 to bit 8 at each frame transmission.";
CM_ SG_ 294 CRC_MCPB_PROPULSION "CRC according to SAE J1850 standard that has to be calculated from bit 63 to bit 8 at each frame transmission.";
CM_ SG_ 293 MCPA_Torque_Achieved_V_P "Achieved Torque value Validity, [1] = True";
CM_ SG_ 293 MCPA_Torque_Achieved_P "Motor A Torque Achieved";
CM_ SG_ 293 MCPA_TorqAchieved_AEMD_V_P "Motor Torque Achieved Validity";
CM_ SG_ 293 MCPA_TorqAchieved_AEMD_P "Motor Torque Achieved without AEMD";
CM_ SG_ 293 MCPA_Temp_P "Motor Stator Temperature";
CM_ SG_ 293 MCPA_SPT_Stat_P "Inverter Isolation Status";
CM_ SG_ 293 MCPA_Spd_Lim_P "Limited motor speed during reduced performance from MCPA";
CM_ SG_ 293 MCPA_RPM_V_P "Motor A Speed Validity, [1] = True";
CM_ SG_ 293 MCPA_RPM_P "Motor A Speed Raw";
CM_ SG_ 293 MCPA_MtrMinCpbltyTrq_P "Motor A Min Capability Torque";
CM_ SG_ 293 MCPA_MtrMaxCpbltyTrq_P "Motor A Max Capability Torque";
CM_ SG_ 293 MCPA_MtrIndex_P "Motor A Capability Curve Array Index";
CM_ SG_ 293 MCPA_MinTorq_P "Motor A Minimum Torque";
CM_ SG_ 293 MCPA_MaxTorq_P "Motor A Maximum Torque";
CM_ SG_ 293 MCPA_Invrtr_State_P "Inverter State of Operation of Motor A";
CM_ SG_ 293 MCPA_InterlockSts_P "Front inverter interlock state";
CM_ SG_ 293 MCPA_HV_CnctrOpn_Req_P "HV Battery pack contactor request";
CM_ SG_ 293 MCPA_Dschrge_Status_P "The active discharge status of MCPA";
CM_ SG_ 293 MCPA_DeratingFactor_P "Motor A Derating Factor";
CM_ SG_ 293 MCPA_CpbltySpdDivVolt_P "Motor A Speed at Capability Curve";
CM_ SG_ 293 MCPA_AccelRawV_P "Motor A Acceleration Validity";
CM_ SG_ 293 MCPA_AccelRaw_P "Motor A Acceleration";
CM_ SG_ 293 MCPA_AC_Isolation_Status_P "Motor AC Isolation Status";
CM_ SG_ 293 MCPA_6SO_Status_P "Motor A 6SO Status";
CM_ SG_ 293 MCPA_3PS_Pos_P "3 phase motor short possible from MCP B; True = [1]";
CM_ SG_ 293 MC_MCPA_PROPULSION "Message counter according to SAE J1850 standard that has to be calculated from bit 63 to bit 8 at each frame transmission.";
CM_ SG_ 293 CRC_MCPA_PROPULSION "CRC according to SAE J1850 standard that has to be calculated from bit 63 to bit 8 at each frame transmission.";
BA_DEF_ BU_ "NwmNodeType" ENUM "+15_NotWakeable","+30_Wakeable","+30_NotWakeable","kMaster","kSlave15","kSlave30","none";
BA_DEF_ BU_ "NmNodeType" ENUM "+15_NotWakeable","+30_Wakeable","+30_NotWakeable","kMaster","kSlave15","kSlave30","none";
BA_DEF_ BU_ "NmAsrCanMsgReducedTime" INT 1 65535;
BA_DEF_ BU_ "NmAsrNodeIdentifier" HEX 0 255;
BA_DEF_ BU_ "NmAsrNode" ENUM "No","Yes";
BA_DEF_ BU_ "NmNode" ENUM "No","Yes";
BA_DEF_ BU_ "NmStationAddress" HEX 0 255;
BA_DEF_ BU_ "Description" STRING ;
BA_DEF_ "VersionYear" INT 0 99;
BA_DEF_ "VersionWeek" INT 0 53;
BA_DEF_ "Version" HEX 0 255;
BA_DEF_ "NmAsrCanMsgCycleTime" INT 1 65535;
BA_DEF_ "NmAsrBaseAddress" HEX 235487232 2147483647;
BA_DEF_ "NmAsrMessageCount" INT 1 256;
BA_DEF_ "NmAsrRepeatMessageTime" INT 1 65535;
BA_DEF_ "NmAsrWaitBusSleepTime" INT 1 65535;
BA_DEF_ "NmAsrTimeoutTime" INT 1 65535;
BA_DEF_ "DBName" STRING ;
BA_DEF_ "Baudrate" INT 0 1000000;
BA_DEF_ "BusType" STRING ;
BA_DEF_ "NmType" STRING ;
BA_DEF_ "Manufacturer" STRING ;
BA_DEF_ BO_ "CANFD_BRS" ENUM "0","1";
BA_DEF_ BO_ "VFrameFormat" ENUM "StandardCAN","ExtendedCAN","reserved","reserved","reserved","reserved","reserved","reserved","reserved","reserved","reserved","reserved","reserved","reserved","StandardCAN_FD","ExtendedCAN_FD";
BA_DEF_ BO_ "DiagConnection" HEX 0 65535;
BA_DEF_ BO_ "DiagState" ENUM "No","Yes";
BA_DEF_ BO_ "NmAsrMessage" ENUM "No","Yes";
BA_DEF_ BO_ "GenMsgDelayTime" INT 0 65535;
BA_DEF_ BO_ "GenMsgCycleTime" INT 0 65535;
BA_DEF_ BO_ "GenMsgCycleTimeFast" INT 0 65535;
BA_DEF_ BO_ "GenMsgStartDelayTime" INT 0 65535;
BA_DEF_ BO_ "GenMsgILSupport" ENUM "No","Yes";
BA_DEF_ BO_ "GenMsgNrOfRepetition" INT 0 255;
BA_DEF_ BO_ "GenMsgSendType" ENUM "Cyclic","NotUsed","NotUsed","NotUsed","NotUsed","NotUsed","NotUsed","NotUsed","NoMsgSendType";
BA_DEF_ BO_ "NmMessage" ENUM "No","Yes";
BA_DEF_ BO_ "DiagResponse" ENUM "No","Yes";
BA_DEF_ BO_ "Type" ENUM "P","C","PE","COC","PE_Cntrl","E","E_Cntrl","OC","S","BAF","DC","EM","MM","ISO-TP","-";
BA_DEF_ BO_ "DiagRequest" ENUM "No","Yes";
BA_DEF_ SG_ "GenSigTimeoutTime_MCPB" INT 0 65535;
BA_DEF_ SG_ "GenSigTimeoutTime_MCPA" INT 0 65535;
BA_DEF_ SG_ "GenSigTimeoutTime_EVCU2" INT 0 65535;
BA_DEF_ SG_ "GenSigTimeoutTime_AGSM" INT 0 65535;
BA_DEF_ SG_ "SystemSignalLongSymbol" STRING ;
BA_DEF_ SG_ "GenSigSendType" ENUM "NotUsed","OnWrite","OnWriteWithRepetition","OnChange","OnChangeWithRepetition","IfActive","IfActiveWithRepetition","NoSigSendType";
BA_DEF_ SG_ "GenSigInactiveValue" INT 0 2147483647;
BA_DEF_ SG_ "GenSigStartValue" INT 0 2147483647;
BA_DEF_DEF_ "NwmNodeType" "none";
BA_DEF_DEF_ "NmNodeType" "none";
BA_DEF_DEF_ "NmAsrCanMsgReducedTime" 100;
BA_DEF_DEF_ "NmAsrNodeIdentifier" 0;
BA_DEF_DEF_ "NmAsrNode" "Yes";
BA_DEF_DEF_ "NmNode" "Yes";
BA_DEF_DEF_ "NmStationAddress" 0;
BA_DEF_DEF_ "Description" "";
BA_DEF_DEF_ "VersionYear" 23;
BA_DEF_DEF_ "VersionWeek" 46;
BA_DEF_DEF_ "Version" 160;
BA_DEF_DEF_ "NmAsrCanMsgCycleTime" 200;
BA_DEF_DEF_ "NmAsrBaseAddress" 506724352;
BA_DEF_DEF_ "NmAsrMessageCount" 256;
BA_DEF_DEF_ "NmAsrRepeatMessageTime" 800;
BA_DEF_DEF_ "NmAsrWaitBusSleepTime" 750;
BA_DEF_DEF_ "NmAsrTimeoutTime" 1000;
BA_DEF_DEF_ "DBName" "CAN";
BA_DEF_DEF_ "Baudrate" 500000;
BA_DEF_DEF_ "BusType" "CAN";
BA_DEF_DEF_ "NmType" "";
BA_DEF_DEF_ "Manufacturer" "Fiat";
BA_DEF_DEF_ "CANFD_BRS" "0";
BA_DEF_DEF_ "VFrameFormat" "StandardCAN_FD";
BA_DEF_DEF_ "DiagConnection" 0;
BA_DEF_DEF_ "DiagState" "No";
BA_DEF_DEF_ "NmAsrMessage" "No";
BA_DEF_DEF_ "GenMsgDelayTime" 0;
BA_DEF_DEF_ "GenMsgCycleTime" 0;
BA_DEF_DEF_ "GenMsgCycleTimeFast" 0;
BA_DEF_DEF_ "GenMsgStartDelayTime" 0;
BA_DEF_DEF_ "GenMsgILSupport" "No";
BA_DEF_DEF_ "GenMsgNrOfRepetition" 0;
BA_DEF_DEF_ "GenMsgSendType" "NoMsgSendType";
BA_DEF_DEF_ "NmMessage" "No";
BA_DEF_DEF_ "DiagResponse" "No";
BA_DEF_DEF_ "Type" "-";
BA_DEF_DEF_ "DiagRequest" "No";
BA_DEF_DEF_ "GenSigTimeoutTime_MCPB" 2500;
BA_DEF_DEF_ "GenSigTimeoutTime_MCPA" 2500;
BA_DEF_DEF_ "GenSigTimeoutTime_EVCU2" 2500;
BA_DEF_DEF_ "GenSigTimeoutTime_AGSM" 2500;
BA_DEF_DEF_ "SystemSignalLongSymbol" "";
BA_DEF_DEF_ "GenSigSendType" "NoSigSendType";
BA_DEF_DEF_ "GenSigInactiveValue" 0;
BA_DEF_DEF_ "GenSigStartValue" 0;
BA_ "NmAsrCanMsgCycleTime" 1000;
BA_ "NmAsrBaseAddress" 507002880;
BA_ "NmAsrRepeatMessageTime" 5000;
BA_ "NmAsrWaitBusSleepTime" 1000;
BA_ "NmAsrTimeoutTime" 8000;
BA_ "DBName" "FDCAN16";
BA_ "BusType" "CAN FD";
BA_ "NmType" "NmAsr";
BA_ "NwmNodeType" BU_ MCPB 1;
BA_ "NmNodeType" BU_ MCPB 1;
BA_ "NmAsrCanMsgReducedTime" BU_ MCPB 650;
BA_ "NmAsrNodeIdentifier" BU_ MCPB 89;
BA_ "NmStationAddress" BU_ MCPB 89;
BA_ "Description" BU_ MCPB "Motor Control Processor B";
BA_ "NwmNodeType" BU_ MCPA 1;
BA_ "NmNodeType" BU_ MCPA 1;
BA_ "NmAsrCanMsgReducedTime" BU_ MCPA 625;
BA_ "NmAsrNodeIdentifier" BU_ MCPA 88;
BA_ "NmStationAddress" BU_ MCPA 88;
BA_ "Description" BU_ MCPA "Motor Control Processor A";
BA_ "NwmNodeType" BU_ EVCU2 1;
BA_ "NmNodeType" BU_ EVCU2 1;
BA_ "NmAsrCanMsgReducedTime" BU_ EVCU2 950;
BA_ "NmAsrNodeIdentifier" BU_ EVCU2 64;
BA_ "NmStationAddress" BU_ EVCU2 64;
BA_ "Description" BU_ EVCU2 "Electric Vehicle Control Unit 2";
BA_ "NwmNodeType" BU_ AGSM 0;
BA_ "NmNodeType" BU_ AGSM 0;
BA_ "NmAsrNodeIdentifier" BU_ AGSM 22;
BA_ "NmAsrNode" BU_ AGSM 0;
BA_ "NmNode" BU_ AGSM 0;
BA_ "NmStationAddress" BU_ AGSM 22;
BA_ "Description" BU_ AGSM "Automatic Gearbox Shifter Module";
BA_ "VFrameFormat" BO_ 2564502513 1;
BA_ "DiagConnection" BO_ 2564502513 61747;
BA_ "DiagState" BO_ 2564502513 1;
BA_ "Type" BO_ 2564502513 8;
BA_ "CANFD_BRS" BO_ 156 1;
BA_ "GenMsgILSupport" BO_ 156 1;
BA_ "Type" BO_ 156 8;
BA_ "CANFD_BRS" BO_ 1829 1;
BA_ "GenMsgCycleTime" BO_ 1829 1000;
BA_ "GenMsgILSupport" BO_ 1829 1;
BA_ "GenMsgSendType" BO_ 1829 0;
BA_ "Type" BO_ 1829 1;
BA_ "CANFD_BRS" BO_ 1626 1;
BA_ "GenMsgCycleTime" BO_ 1626 500;
BA_ "GenMsgCycleTimeFast" BO_ 1626 10;
BA_ "GenMsgILSupport" BO_ 1626 1;
BA_ "GenMsgSendType" BO_ 1626 0;
BA_ "Type" BO_ 1626 10;
BA_ "CANFD_BRS" BO_ 2564554482 1;
BA_ "VFrameFormat" BO_ 2564554482 15;
BA_ "DiagConnection" BO_ 2564554482 62206;
BA_ "DiagState" BO_ 2564554482 1;
BA_ "Type" BO_ 2564554482 8;
BA_ "CANFD_BRS" BO_ 1155 1;
BA_ "GenMsgDelayTime" BO_ 1155 20;
BA_ "GenMsgCycleTime" BO_ 1155 500;
BA_ "GenMsgCycleTimeFast" BO_ 1155 20;
BA_ "GenMsgILSupport" BO_ 1155 1;
BA_ "GenMsgNrOfRepetition" BO_ 1155 2;
BA_ "GenMsgSendType" BO_ 1155 0;
BA_ "Type" BO_ 1155 3;
BA_ "CANFD_BRS" BO_ 609 1;
BA_ "GenMsgCycleTime" BO_ 609 100;
BA_ "GenMsgCycleTimeFast" BO_ 609 20;
BA_ "GenMsgStartDelayTime" BO_ 609 50;
BA_ "GenMsgILSupport" BO_ 609 1;
BA_ "GenMsgNrOfRepetition" BO_ 609 2;
BA_ "GenMsgSendType" BO_ 609 0;
BA_ "Type" BO_ 609 3;
BA_ "CANFD_BRS" BO_ 1066 1;
BA_ "GenMsgDelayTime" BO_ 1066 20;
BA_ "GenMsgCycleTime" BO_ 1066 250;
BA_ "GenMsgCycleTimeFast" BO_ 1066 20;
BA_ "GenMsgILSupport" BO_ 1066 1;
BA_ "GenMsgNrOfRepetition" BO_ 1066 2;
BA_ "GenMsgSendType" BO_ 1066 0;
BA_ "Type" BO_ 1066 3;
BA_ "CANFD_BRS" BO_ 1153 1;
BA_ "GenMsgDelayTime" BO_ 1153 20;
BA_ "GenMsgCycleTime" BO_ 1153 500;
BA_ "GenMsgCycleTimeFast" BO_ 1153 20;
BA_ "GenMsgILSupport" BO_ 1153 1;
BA_ "GenMsgNrOfRepetition" BO_ 1153 2;
BA_ "GenMsgSendType" BO_ 1153 0;
BA_ "Type" BO_ 1153 3;
BA_ "CANFD_BRS" BO_ 1032 1;
BA_ "GenMsgCycleTime" BO_ 1032 100;
BA_ "GenMsgILSupport" BO_ 1032 1;
BA_ "GenMsgSendType" BO_ 1032 0;
BA_ "Type" BO_ 1032 1;
BA_ "CANFD_BRS" BO_ 267 1;
BA_ "GenMsgCycleTime" BO_ 267 10;
BA_ "GenMsgILSupport" BO_ 267 1;
BA_ "GenMsgSendType" BO_ 267 0;
BA_ "Type" BO_ 267 1;
BA_ "CANFD_BRS" BO_ 1033 1;
BA_ "GenMsgCycleTime" BO_ 1033 100;
BA_ "GenMsgILSupport" BO_ 1033 1;
BA_ "GenMsgSendType" BO_ 1033 0;
BA_ "Type" BO_ 1033 1;
BA_ "CANFD_BRS" BO_ 276 1;
BA_ "GenMsgCycleTime" BO_ 276 10;
BA_ "GenMsgILSupport" BO_ 276 1;
BA_ "GenMsgSendType" BO_ 276 0;
BA_ "Type" BO_ 276 1;
BA_ "CANFD_BRS" BO_ 258 1;
BA_ "GenMsgCycleTime" BO_ 258 10;
BA_ "GenMsgILSupport" BO_ 258 1;
BA_ "GenMsgSendType" BO_ 258 0;
BA_ "Type" BO_ 258 1;
BA_ "CANFD_BRS" BO_ 476 1;
BA_ "GenMsgDelayTime" BO_ 476 15;
BA_ "GenMsgCycleTime" BO_ 476 20;
BA_ "GenMsgCycleTimeFast" BO_ 476 20;
BA_ "GenMsgILSupport" BO_ 476 1;
BA_ "GenMsgNrOfRepetition" BO_ 476 2;
BA_ "GenMsgSendType" BO_ 476 0;
BA_ "Type" BO_ 476 3;
BA_ "CANFD_BRS" BO_ 2654486617 1;
BA_ "VFrameFormat" BO_ 2654486617 15;
BA_ "NmAsrMessage" BO_ 2654486617 1;
BA_ "NmMessage" BO_ 2654486617 1;
BA_ "Type" BO_ 2654486617 8;
BA_ "CANFD_BRS" BO_ 2654486616 1;
BA_ "VFrameFormat" BO_ 2654486616 15;
BA_ "NmAsrMessage" BO_ 2654486616 1;
BA_ "NmMessage" BO_ 2654486616 1;
BA_ "Type" BO_ 2654486616 8;
BA_ "CANFD_BRS" BO_ 496 1;
BA_ "GenMsgCycleTime" BO_ 496 10;
BA_ "GenMsgILSupport" BO_ 496 1;
BA_ "GenMsgSendType" BO_ 496 0;
BA_ "Type" BO_ 496 1;
BA_ "CANFD_BRS" BO_ 105 1;
BA_ "GenMsgDelayTime" BO_ 105 100;
BA_ "GenMsgCycleTime" BO_ 105 1000;
BA_ "GenMsgILSupport" BO_ 105 1;
BA_ "GenMsgSendType" BO_ 105 0;
BA_ "Type" BO_ 105 3;
BA_ "CANFD_BRS" BO_ 263 1;
BA_ "GenMsgCycleTime" BO_ 263 10;
BA_ "GenMsgILSupport" BO_ 263 1;
BA_ "GenMsgSendType" BO_ 263 0;
BA_ "Type" BO_ 263 1;
BA_ "GenMsgCycleTime" BO_ 216 10;
BA_ "GenMsgILSupport" BO_ 216 1;
BA_ "GenMsgSendType" BO_ 216 0;
BA_ "Type" BO_ 216 1;
BA_ "CANFD_BRS" BO_ 216 1;
BA_ "CANFD_BRS" BO_ 2654486592 1;
BA_ "VFrameFormat" BO_ 2654486592 15;
BA_ "NmAsrMessage" BO_ 2654486592 1;
BA_ "NmMessage" BO_ 2654486592 1;
BA_ "Type" BO_ 2654486592 8;
BA_ "CANFD_BRS" BO_ 1811 1;
BA_ "GenMsgDelayTime" BO_ 1811 20;
BA_ "GenMsgCycleTime" BO_ 1811 1000;
BA_ "GenMsgILSupport" BO_ 1811 1;
BA_ "GenMsgSendType" BO_ 1811 0;
BA_ "Type" BO_ 1811 1;
BA_ "CANFD_BRS" BO_ 1065 1;
BA_ "GenMsgCycleTime" BO_ 1065 100;
BA_ "GenMsgILSupport" BO_ 1065 1;
BA_ "GenMsgSendType" BO_ 1065 0;
BA_ "Type" BO_ 1065 1;
BA_ "CANFD_BRS" BO_ 1057 1;
BA_ "GenMsgCycleTime" BO_ 1057 100;
BA_ "GenMsgILSupport" BO_ 1057 1;
BA_ "GenMsgSendType" BO_ 1057 0;
BA_ "Type" BO_ 1057 1;
BA_ "CANFD_BRS" BO_ 504 1;
BA_ "GenMsgCycleTime" BO_ 504 20;
BA_ "GenMsgILSupport" BO_ 504 1;
BA_ "GenMsgSendType" BO_ 504 0;
BA_ "Type" BO_ 504 1;
BA_ "CANFD_BRS" BO_ 503 1;
BA_ "GenMsgCycleTime" BO_ 503 20;
BA_ "GenMsgILSupport" BO_ 503 1;
BA_ "GenMsgSendType" BO_ 503 0;
BA_ "Type" BO_ 503 1;
BA_ "CANFD_BRS" BO_ 297 1;
BA_ "GenMsgCycleTime" BO_ 297 10;
BA_ "GenMsgILSupport" BO_ 297 1;
BA_ "GenMsgSendType" BO_ 297 0;
BA_ "Type" BO_ 297 1;
BA_ "CANFD_BRS" BO_ 296 1;
BA_ "GenMsgCycleTime" BO_ 296 10;
BA_ "GenMsgILSupport" BO_ 296 1;
BA_ "GenMsgSendType" BO_ 296 0;
BA_ "Type" BO_ 296 1;
BA_ "CANFD_BRS" BO_ 124 1;
BA_ "GenMsgILSupport" BO_ 124 1;
BA_ "Type" BO_ 124 8;
BA_ "CANFD_BRS" BO_ 127 1;
BA_ "GenMsgILSupport" BO_ 127 1;
BA_ "Type" BO_ 127 8;
BA_ "CANFD_BRS" BO_ 123 1;
BA_ "GenMsgILSupport" BO_ 123 1;
BA_ "Type" BO_ 123 8;
BA_ "Type" BO_ 126 8;
BA_ "CANFD_BRS" BO_ 126 1;
BA_ "GenMsgILSupport" BO_ 126 1;
BA_ "CANFD_BRS" BO_ 294 1;
BA_ "GenMsgCycleTime" BO_ 294 10;
BA_ "GenMsgILSupport" BO_ 294 1;
BA_ "GenMsgSendType" BO_ 294 0;
BA_ "Type" BO_ 294 1;
BA_ "CANFD_BRS" BO_ 293 1;
BA_ "GenMsgCycleTime" BO_ 293 10;
BA_ "GenMsgILSupport" BO_ 293 1;
BA_ "GenMsgSendType" BO_ 293 0;
BA_ "Type" BO_ 293 1;
BA_ "GenSigTimeoutTime_EVCU2" SG_ 156 GPS_Date_Day 0;
BA_ "GenSigTimeoutTime_AGSM" SG_ 156 GPS_Date_Day 0;
BA_ "GenSigStartValue" SG_ 156 GPS_Date_Day 255;
BA_ "GenSigTimeoutTime_EVCU2" SG_ 156 GPS_Date_Month 0;
BA_ "GenSigTimeoutTime_AGSM" SG_ 156 GPS_Date_Month 0;
BA_ "GenSigStartValue" SG_ 156 GPS_Date_Month 255;
BA_ "GenSigTimeoutTime_EVCU2" SG_ 156 GPS_Date_Year 0;
BA_ "GenSigTimeoutTime_AGSM" SG_ 156 GPS_Date_Year 0;
BA_ "GenSigStartValue" SG_ 156 GPS_Date_Year 65535;
BA_ "GenSigTimeoutTime_EVCU2" SG_ 156 GPS_UTC_Hour 0;
BA_ "GenSigTimeoutTime_AGSM" SG_ 156 GPS_UTC_Hour 0;
BA_ "GenSigStartValue" SG_ 156 GPS_UTC_Hour 255;
BA_ "GenSigTimeoutTime_EVCU2" SG_ 156 GPS_UTC_Minute 0;
BA_ "GenSigTimeoutTime_AGSM" SG_ 156 GPS_UTC_Minute 0;
BA_ "GenSigStartValue" SG_ 156 GPS_UTC_Minute 255;
BA_ "GenSigTimeoutTime_EVCU2" SG_ 156 GPS_UTC_Second 0;
BA_ "GenSigTimeoutTime_AGSM" SG_ 156 GPS_UTC_Second 0;
BA_ "GenSigStartValue" SG_ 156 GPS_UTC_Second 65535;
BA_ "GenSigTimeoutTime_EVCU2" SG_ 105 T7_Sensor_Temp 0;
BA_ "GenSigTimeoutTime_AGSM" SG_ 105 T7_Sensor_Temp 0;
BA_ "GenSigSendType" SG_ 105 T7_Sensor_Temp 3;
BA_ "GenSigTimeoutTime_MCPB" SG_ 263 GearEngagedForDisplay_PT 0;
BA_ "GenSigTimeoutTime_MCPA" SG_ 263 GearEngagedForDisplay_PT 0;
BA_ "GenSigTimeoutTime_EVCU2" SG_ 263 GearEngagedForDisplay_PT 0;
BA_ "GenSigTimeoutTime_EVCU2" SG_ 105 T4_Sensor_Temp 0;
BA_ "GenSigTimeoutTime_AGSM" SG_ 105 T4_Sensor_Temp 0;
BA_ "GenSigSendType" SG_ 105 T4_Sensor_Temp 3;
BA_ "GenSigTimeoutTime_EVCU2" SG_ 105 T7_CoolantTempVldty 0;
BA_ "GenSigTimeoutTime_AGSM" SG_ 105 T7_CoolantTempVldty 0;
BA_ "GenSigSendType" SG_ 105 T7_CoolantTempVldty 3;
BA_ "GenSigTimeoutTime_MCPB" SG_ 263 GearIndicationSts_PT 0;
BA_ "GenSigTimeoutTime_MCPA" SG_ 263 GearIndicationSts_PT 0;
BA_ "GenSigTimeoutTime_EVCU2" SG_ 263 GearIndicationSts_PT 0;
BA_ "GenSigTimeoutTime_MCPA" SG_ 263 MessageCounter_PT_SYSTEM_FD_1 0;
BA_ "GenSigTimeoutTime_EVCU2" SG_ 263 MessageCounter_PT_SYSTEM_FD_1 0;
BA_ "GenSigTimeoutTime_AGSM" SG_ 263 MessageCounter_PT_SYSTEM_FD_1 0;
BA_ "GenSigTimeoutTime_MCPB" SG_ 263 ShiftLeverPosition_PT 0;
BA_ "GenSigTimeoutTime_MCPA" SG_ 263 ShiftLeverPosition_PT 0;
BA_ "GenSigTimeoutTime_EVCU2" SG_ 263 ShiftLeverPosition_PT 0;
BA_ "GenSigTimeoutTime_MCPB" SG_ 263 TransmissionFailSts_PT 0;
BA_ "GenSigTimeoutTime_MCPA" SG_ 263 TransmissionFailSts_PT 0;
BA_ "GenSigTimeoutTime_EVCU2" SG_ 263 TransmissionFailSts_PT 0;
BA_ "GenSigTimeoutTime_EVCU2" SG_ 1811 Real_Time_Validity 0;
BA_ "GenSigTimeoutTime_AGSM" SG_ 1811 Real_Time_Validity 0;
BA_ "GenSigTimeoutTime_EVCU2" SG_ 1811 Real_Time_Clock 0;
BA_ "GenSigTimeoutTime_AGSM" SG_ 1811 Real_Time_Clock 0;
BA_ "GenSigTimeoutTime_MCPB" SG_ 496 Plock_fdbk_sts 0;
BA_ "GenSigTimeoutTime_MCPA" SG_ 496 Plock_fdbk_sts 0;
BA_ "GenSigTimeoutTime_AGSM" SG_ 496 Plock_fdbk_sts 0;
BA_ "GenSigTimeoutTime_EVCU2" SG_ 216 BatteryVoltage_Raw_PT 0;
BA_ "GenSigTimeoutTime_AGSM" SG_ 216 BatteryVoltage_Raw_PT 0;
BA_ "GenSigTimeoutTime_MCPB" SG_ 263 APCM_Rq_PT 0;
BA_ "GenSigTimeoutTime_MCPA" SG_ 263 APCM_Rq_PT 0;
BA_ "GenSigTimeoutTime_EVCU2" SG_ 263 APCM_Rq_PT 0;
BA_ "GenSigTimeoutTime_MCPA" SG_ 263 CRC_PT_SYSTEM_FD_1 0;
BA_ "GenSigTimeoutTime_EVCU2" SG_ 263 CRC_PT_SYSTEM_FD_1 0;
BA_ "GenSigTimeoutTime_AGSM" SG_ 263 CRC_PT_SYSTEM_FD_1 0;
BA_ "GenSigTimeoutTime_MCPA" SG_ 263 GearEngaged_PT 0;
BA_ "GenSigTimeoutTime_EVCU2" SG_ 263 GearEngaged_PT 0;
BA_ "GenSigTimeoutTime_AGSM" SG_ 263 GearEngaged_PT 0;
BA_ "GenSigTimeoutTime_MCPB" SG_ 2654486592 CBV_bit0_RepeatMessageRequestBit 0;
BA_ "GenSigTimeoutTime_MCPA" SG_ 2654486592 CBV_bit0_RepeatMessageRequestBit 0;
BA_ "GenSigTimeoutTime_EVCU2" SG_ 2654486592 CBV_bit0_RepeatMessageRequestBit 0;
BA_ "GenSigTimeoutTime_AGSM" SG_ 2654486592 CBV_bit0_RepeatMessageRequestBit 0;
BA_ "GenSigTimeoutTime_MCPB" SG_ 2654486592 CBV_bit3_NMCoordinatorBit 0;
BA_ "GenSigTimeoutTime_MCPA" SG_ 2654486592 CBV_bit3_NMCoordinatorBit 0;
BA_ "GenSigTimeoutTime_EVCU2" SG_ 2654486592 CBV_bit3_NMCoordinatorBit 0;
BA_ "GenSigTimeoutTime_AGSM" SG_ 2654486592 CBV_bit3_NMCoordinatorBit 0;
BA_ "GenSigTimeoutTime_MCPB" SG_ 2654486592 CBV_bit4_ActiveWakeupBit 0;
BA_ "GenSigTimeoutTime_MCPA" SG_ 2654486592 CBV_bit4_ActiveWakeupBit 0;
BA_ "GenSigTimeoutTime_EVCU2" SG_ 2654486592 CBV_bit4_ActiveWakeupBit 0;
BA_ "GenSigTimeoutTime_AGSM" SG_ 2654486592 CBV_bit4_ActiveWakeupBit 0;
BA_ "GenSigTimeoutTime_MCPB" SG_ 2654486616 CBV_bit3_NMCoordinatorBit 0;
BA_ "GenSigTimeoutTime_MCPA" SG_ 2654486616 CBV_bit3_NMCoordinatorBit 0;
BA_ "GenSigTimeoutTime_EVCU2" SG_ 2654486616 CBV_bit3_NMCoordinatorBit 0;
BA_ "GenSigTimeoutTime_AGSM" SG_ 2654486616 CBV_bit3_NMCoordinatorBit 0;
BA_ "GenSigTimeoutTime_MCPB" SG_ 2654486617 CBV_bit3_NMCoordinatorBit 0;
BA_ "GenSigTimeoutTime_MCPA" SG_ 2654486617 CBV_bit3_NMCoordinatorBit 0;
BA_ "GenSigTimeoutTime_EVCU2" SG_ 2654486617 CBV_bit3_NMCoordinatorBit 0;
BA_ "GenSigTimeoutTime_AGSM" SG_ 2654486617 CBV_bit3_NMCoordinatorBit 0;
BA_ "GenSigTimeoutTime_MCPB" SG_ 2654486616 CBV_bit4_ActiveWakeupBit 0;
BA_ "GenSigTimeoutTime_MCPA" SG_ 2654486616 CBV_bit4_ActiveWakeupBit 0;
BA_ "GenSigTimeoutTime_EVCU2" SG_ 2654486616 CBV_bit4_ActiveWakeupBit 0;
BA_ "GenSigTimeoutTime_AGSM" SG_ 2654486616 CBV_bit4_ActiveWakeupBit 0;
BA_ "GenSigTimeoutTime_MCPB" SG_ 2654486617 CBV_bit4_ActiveWakeupBit 0;
BA_ "GenSigTimeoutTime_MCPA" SG_ 2654486617 CBV_bit4_ActiveWakeupBit 0;
BA_ "GenSigTimeoutTime_EVCU2" SG_ 2654486617 CBV_bit4_ActiveWakeupBit 0;
BA_ "GenSigTimeoutTime_AGSM" SG_ 2654486617 CBV_bit4_ActiveWakeupBit 0;
BA_ "GenSigTimeoutTime_MCPB" SG_ 2654486617 CBV_bit5 0;
BA_ "GenSigTimeoutTime_MCPA" SG_ 2654486617 CBV_bit5 0;
BA_ "GenSigTimeoutTime_EVCU2" SG_ 2654486617 CBV_bit5 0;
BA_ "GenSigTimeoutTime_AGSM" SG_ 2654486617 CBV_bit5 0;
BA_ "GenSigTimeoutTime_MCPB" SG_ 2654486616 CBV_bit5 0;
BA_ "GenSigTimeoutTime_MCPA" SG_ 2654486616 CBV_bit5 0;
BA_ "GenSigTimeoutTime_EVCU2" SG_ 2654486616 CBV_bit5 0;
BA_ "GenSigTimeoutTime_AGSM" SG_ 2654486616 CBV_bit5 0;
BA_ "GenSigTimeoutTime_MCPB" SG_ 2654486592 CBV_bit1 0;
BA_ "GenSigTimeoutTime_MCPA" SG_ 2654486592 CBV_bit1 0;
BA_ "GenSigTimeoutTime_EVCU2" SG_ 2654486592 CBV_bit1 0;
BA_ "GenSigTimeoutTime_AGSM" SG_ 2654486592 CBV_bit1 0;
BA_ "GenSigTimeoutTime_MCPB" SG_ 2654486592 CBV_bit2 0;
BA_ "GenSigTimeoutTime_MCPA" SG_ 2654486592 CBV_bit2 0;
BA_ "GenSigTimeoutTime_EVCU2" SG_ 2654486592 CBV_bit2 0;
BA_ "GenSigTimeoutTime_AGSM" SG_ 2654486592 CBV_bit2 0;
BA_ "GenSigTimeoutTime_MCPB" SG_ 2654486616 CBV_bit2 0;
BA_ "GenSigTimeoutTime_MCPA" SG_ 2654486616 CBV_bit2 0;
BA_ "GenSigTimeoutTime_EVCU2" SG_ 2654486616 CBV_bit2 0;
BA_ "GenSigTimeoutTime_AGSM" SG_ 2654486616 CBV_bit2 0;
BA_ "GenSigTimeoutTime_MCPB" SG_ 2654486617 CBV_bit2 0;
BA_ "GenSigTimeoutTime_MCPA" SG_ 2654486617 CBV_bit2 0;
BA_ "GenSigTimeoutTime_EVCU2" SG_ 2654486617 CBV_bit2 0;
BA_ "GenSigTimeoutTime_AGSM" SG_ 2654486617 CBV_bit2 0;
BA_ "GenSigTimeoutTime_MCPB" SG_ 2654486616 CBV_bit1 0;
BA_ "GenSigTimeoutTime_MCPA" SG_ 2654486616 CBV_bit1 0;
BA_ "GenSigTimeoutTime_EVCU2" SG_ 2654486616 CBV_bit1 0;
BA_ "GenSigTimeoutTime_AGSM" SG_ 2654486616 CBV_bit1 0;
BA_ "GenSigTimeoutTime_MCPB" SG_ 2654486617 CBV_bit1 0;
BA_ "GenSigTimeoutTime_MCPA" SG_ 2654486617 CBV_bit1 0;
BA_ "GenSigTimeoutTime_EVCU2" SG_ 2654486617 CBV_bit1 0;
BA_ "GenSigTimeoutTime_AGSM" SG_ 2654486617 CBV_bit1 0;
BA_ "GenSigTimeoutTime_MCPB" SG_ 2654486616 CBV_bit0_RepeatMessageRequestBit 0;
BA_ "GenSigTimeoutTime_MCPA" SG_ 2654486616 CBV_bit0_RepeatMessageRequestBit 0;
BA_ "GenSigTimeoutTime_EVCU2" SG_ 2654486616 CBV_bit0_RepeatMessageRequestBit 0;
BA_ "GenSigTimeoutTime_AGSM" SG_ 2654486616 CBV_bit0_RepeatMessageRequestBit 0;
BA_ "GenSigTimeoutTime_MCPB" SG_ 2654486617 CBV_bit0_RepeatMessageRequestBit 0;
BA_ "GenSigTimeoutTime_MCPA" SG_ 2654486617 CBV_bit0_RepeatMessageRequestBit 0;
BA_ "GenSigTimeoutTime_EVCU2" SG_ 2654486617 CBV_bit0_RepeatMessageRequestBit 0;
BA_ "GenSigTimeoutTime_AGSM" SG_ 2654486617 CBV_bit0_RepeatMessageRequestBit 0;
BA_ "GenSigTimeoutTime_MCPB" SG_ 2654486616 SourceNodeIdentifier 0;
BA_ "GenSigTimeoutTime_MCPA" SG_ 2654486616 SourceNodeIdentifier 0;
BA_ "GenSigTimeoutTime_EVCU2" SG_ 2654486616 SourceNodeIdentifier 0;
BA_ "GenSigTimeoutTime_AGSM" SG_ 2654486616 SourceNodeIdentifier 0;
BA_ "GenSigTimeoutTime_MCPB" SG_ 2654486617 SourceNodeIdentifier 0;
BA_ "GenSigTimeoutTime_MCPA" SG_ 2654486617 SourceNodeIdentifier 0;
BA_ "GenSigTimeoutTime_EVCU2" SG_ 2654486617 SourceNodeIdentifier 0;
BA_ "GenSigTimeoutTime_AGSM" SG_ 2654486617 SourceNodeIdentifier 0;
BA_ "GenSigTimeoutTime_MCPB" SG_ 2654486592 CBV_bit7 0;
BA_ "GenSigTimeoutTime_MCPA" SG_ 2654486592 CBV_bit7 0;
BA_ "GenSigTimeoutTime_EVCU2" SG_ 2654486592 CBV_bit7 0;
BA_ "GenSigTimeoutTime_AGSM" SG_ 2654486592 CBV_bit7 0;
BA_ "GenSigTimeoutTime_MCPB" SG_ 2654486592 SourceNodeIdentifier 0;
BA_ "GenSigTimeoutTime_MCPA" SG_ 2654486592 SourceNodeIdentifier 0;
BA_ "GenSigTimeoutTime_EVCU2" SG_ 2654486592 SourceNodeIdentifier 0;
BA_ "GenSigTimeoutTime_AGSM" SG_ 2654486592 SourceNodeIdentifier 0;
BA_ "GenSigTimeoutTime_MCPB" SG_ 2654486617 CBV_bit7 0;
BA_ "GenSigTimeoutTime_MCPA" SG_ 2654486617 CBV_bit7 0;
BA_ "GenSigTimeoutTime_EVCU2" SG_ 2654486617 CBV_bit7 0;
BA_ "GenSigTimeoutTime_AGSM" SG_ 2654486617 CBV_bit7 0;
BA_ "GenSigTimeoutTime_MCPB" SG_ 2654486616 CBV_bit7 0;
BA_ "GenSigTimeoutTime_MCPA" SG_ 2654486616 CBV_bit7 0;
BA_ "GenSigTimeoutTime_EVCU2" SG_ 2654486616 CBV_bit7 0;
BA_ "GenSigTimeoutTime_AGSM" SG_ 2654486616 CBV_bit7 0;
BA_ "GenSigTimeoutTime_MCPB" SG_ 2654486592 CBV_bit5 0;
BA_ "GenSigTimeoutTime_MCPA" SG_ 2654486592 CBV_bit5 0;
BA_ "GenSigTimeoutTime_EVCU2" SG_ 2654486592 CBV_bit5 0;
BA_ "GenSigTimeoutTime_AGSM" SG_ 2654486592 CBV_bit5 0;
BA_ "GenSigTimeoutTime_MCPB" SG_ 2654486592 CBV_bit6_PartialNtwInfBit 0;
BA_ "GenSigTimeoutTime_MCPA" SG_ 2654486592 CBV_bit6_PartialNtwInfBit 0;
BA_ "GenSigTimeoutTime_EVCU2" SG_ 2654486592 CBV_bit6_PartialNtwInfBit 0;
BA_ "GenSigTimeoutTime_AGSM" SG_ 2654486592 CBV_bit6_PartialNtwInfBit 0;
BA_ "GenSigTimeoutTime_MCPB" SG_ 2654486616 CBV_bit6_PartialNtwInfBit 0;
BA_ "GenSigTimeoutTime_MCPA" SG_ 2654486616 CBV_bit6_PartialNtwInfBit 0;
BA_ "GenSigTimeoutTime_EVCU2" SG_ 2654486616 CBV_bit6_PartialNtwInfBit 0;
BA_ "GenSigTimeoutTime_AGSM" SG_ 2654486616 CBV_bit6_PartialNtwInfBit 0;
BA_ "GenSigTimeoutTime_MCPB" SG_ 2654486617 CBV_bit6_PartialNtwInfBit 0;
BA_ "GenSigTimeoutTime_MCPA" SG_ 2654486617 CBV_bit6_PartialNtwInfBit 0;
BA_ "GenSigTimeoutTime_EVCU2" SG_ 2654486617 CBV_bit6_PartialNtwInfBit 0;
BA_ "GenSigTimeoutTime_AGSM" SG_ 2654486617 CBV_bit6_PartialNtwInfBit 0;
BA_ "GenSigTimeoutTime_MCPB" SG_ 504 MCPB_DerateReason_P 0;
BA_ "GenSigTimeoutTime_MCPA" SG_ 504 MCPB_DerateReason_P 0;
BA_ "GenSigTimeoutTime_AGSM" SG_ 504 MCPB_DerateReason_P 0;
BA_ "GenSigTimeoutTime_MCPB" SG_ 504 CRC_MCPB_STATUS 0;
BA_ "GenSigTimeoutTime_MCPA" SG_ 504 CRC_MCPB_STATUS 0;
BA_ "GenSigTimeoutTime_AGSM" SG_ 504 CRC_MCPB_STATUS 0;
BA_ "GenSigTimeoutTime_MCPB" SG_ 504 MC_MCPB_STATUS 0;
BA_ "GenSigTimeoutTime_MCPA" SG_ 504 MC_MCPB_STATUS 0;
BA_ "GenSigTimeoutTime_AGSM" SG_ 504 MC_MCPB_STATUS 0;
BA_ "GenSigTimeoutTime_MCPB" SG_ 504 MCPB_CoolantTemp_P 0;
BA_ "GenSigTimeoutTime_MCPA" SG_ 504 MCPB_CoolantTemp_P 0;
BA_ "GenSigTimeoutTime_AGSM" SG_ 504 MCPB_CoolantTemp_P 0;
BA_ "GenSigTimeoutTime_MCPB" SG_ 504 MCPB_DC_Current_P 0;
BA_ "GenSigTimeoutTime_MCPA" SG_ 504 MCPB_DC_Current_P 0;
BA_ "GenSigTimeoutTime_AGSM" SG_ 504 MCPB_DC_Current_P 0;
BA_ "GenSigStartValue" SG_ 504 MCPB_DC_Current_P 16384;
BA_ "GenSigTimeoutTime_MCPB" SG_ 504 MCPB_DC_Current_V_P 0;
BA_ "GenSigTimeoutTime_MCPA" SG_ 504 MCPB_DC_Current_V_P 0;
BA_ "GenSigTimeoutTime_AGSM" SG_ 504 MCPB_DC_Current_V_P 0;
BA_ "GenSigTimeoutTime_MCPB" SG_ 504 MCPB_DC_Volt_V_P 0;
BA_ "GenSigTimeoutTime_MCPA" SG_ 504 MCPB_DC_Volt_V_P 0;
BA_ "GenSigTimeoutTime_AGSM" SG_ 504 MCPB_DC_Volt_V_P 0;
BA_ "GenSigTimeoutTime_MCPB" SG_ 504 MCPB_DC_Voltage_P 0;
BA_ "GenSigTimeoutTime_MCPA" SG_ 504 MCPB_DC_Voltage_P 0;
BA_ "GenSigTimeoutTime_AGSM" SG_ 504 MCPB_DC_Voltage_P 0;
BA_ "GenSigTimeoutTime_MCPB" SG_ 504 MCPB_Inverter_Temp_P 0;
BA_ "GenSigTimeoutTime_MCPA" SG_ 504 MCPB_Inverter_Temp_P 0;
BA_ "GenSigTimeoutTime_AGSM" SG_ 504 MCPB_Inverter_Temp_P 0;
BA_ "GenSigStartValue" SG_ 504 MCPB_Inverter_Temp_P 40;
BA_ "GenSigTimeoutTime_MCPB" SG_ 504 MCPB_Control_Board_Temperature_P 0;
BA_ "GenSigTimeoutTime_MCPA" SG_ 504 MCPB_Control_Board_Temperature_P 0;
BA_ "GenSigTimeoutTime_AGSM" SG_ 504 MCPB_Control_Board_Temperature_P 0;
BA_ "GenSigTimeoutTime_MCPB" SG_ 504 MCPB_Service_Lamp_Request_P 0;
BA_ "GenSigTimeoutTime_MCPA" SG_ 504 MCPB_Service_Lamp_Request_P 0;
BA_ "GenSigTimeoutTime_AGSM" SG_ 504 MCPB_Service_Lamp_Request_P 0;
BA_ "GenSigTimeoutTime_MCPB" SG_ 504 MCPB_Rotor_Temperature_P 0;
BA_ "GenSigTimeoutTime_MCPA" SG_ 504 MCPB_Rotor_Temperature_P 0;
BA_ "GenSigTimeoutTime_AGSM" SG_ 504 MCPB_Rotor_Temperature_P 0;
BA_ "GenSigStartValue" SG_ 504 MCPB_Rotor_Temperature_P 255;
BA_ "GenSigTimeoutTime_MCPB" SG_ 504 MCPB_PIM_DC_Side_Busbar_Temp_P 0;
BA_ "GenSigTimeoutTime_MCPA" SG_ 504 MCPB_PIM_DC_Side_Busbar_Temp_P 0;
BA_ "GenSigTimeoutTime_AGSM" SG_ 504 MCPB_PIM_DC_Side_Busbar_Temp_P 0;
BA_ "GenSigTimeoutTime_MCPB" SG_ 504 CLrDiagInfo_MCPB_P 0;
BA_ "GenSigTimeoutTime_MCPA" SG_ 504 CLrDiagInfo_MCPB_P 0;
BA_ "GenSigTimeoutTime_AGSM" SG_ 504 CLrDiagInfo_MCPB_P 0;
BA_ "GenSigTimeoutTime_MCPB" SG_ 294 MCPB_AC_Isolation_Status_P 0;
BA_ "GenSigTimeoutTime_MCPA" SG_ 294 MCPB_AC_Isolation_Status_P 0;
BA_ "GenSigTimeoutTime_AGSM" SG_ 294 MCPB_AC_Isolation_Status_P 0;
BA_ "GenSigTimeoutTime_MCPB" SG_ 503 MCPA_Inverter_Temp_P 0;
BA_ "GenSigTimeoutTime_MCPA" SG_ 503 MCPA_Inverter_Temp_P 0;
BA_ "GenSigTimeoutTime_AGSM" SG_ 503 MCPA_Inverter_Temp_P 0;
BA_ "GenSigStartValue" SG_ 503 MCPA_Inverter_Temp_P 40;
BA_ "GenSigTimeoutTime_MCPB" SG_ 294 MCPB_Temp_P 0;
BA_ "GenSigTimeoutTime_MCPA" SG_ 294 MCPB_Temp_P 0;
BA_ "GenSigTimeoutTime_AGSM" SG_ 294 MCPB_Temp_P 0;
BA_ "GenSigStartValue" SG_ 294 MCPB_Temp_P 40;
BA_ "GenSigTimeoutTime_MCPB" SG_ 294 CRC_MCPB_PROPULSION 0;
BA_ "GenSigTimeoutTime_MCPA" SG_ 294 CRC_MCPB_PROPULSION 0;
BA_ "GenSigTimeoutTime_AGSM" SG_ 294 CRC_MCPB_PROPULSION 0;
BA_ "GenSigTimeoutTime_MCPB" SG_ 294 MC_MCPB_PROPULSION 0;
BA_ "GenSigTimeoutTime_MCPA" SG_ 294 MC_MCPB_PROPULSION 0;
BA_ "GenSigTimeoutTime_AGSM" SG_ 294 MC_MCPB_PROPULSION 0;
BA_ "GenSigTimeoutTime_MCPB" SG_ 294 MCPB_AccelRaw_P 0;
BA_ "GenSigTimeoutTime_MCPA" SG_ 294 MCPB_AccelRaw_P 0;
BA_ "GenSigTimeoutTime_AGSM" SG_ 294 MCPB_AccelRaw_P 0;
BA_ "GenSigStartValue" SG_ 294 MCPB_AccelRaw_P 32768;
BA_ "GenSigTimeoutTime_MCPB" SG_ 294 PlockFailSts_P 0;
BA_ "GenSigTimeoutTime_MCPA" SG_ 294 PlockFailSts_P 0;
BA_ "GenSigTimeoutTime_AGSM" SG_ 294 PlockFailSts_P 0;
BA_ "GenSigTimeoutTime_MCPB" SG_ 294 MCPB_MinTorq_P 0;
BA_ "GenSigTimeoutTime_MCPA" SG_ 294 MCPB_MinTorq_P 0;
BA_ "GenSigTimeoutTime_AGSM" SG_ 294 MCPB_MinTorq_P 0;
BA_ "GenSigStartValue" SG_ 294 MCPB_MinTorq_P 8184;
BA_ "GenSigTimeoutTime_MCPB" SG_ 294 MCPB_MtrIndex_P 0;
BA_ "GenSigTimeoutTime_MCPA" SG_ 294 MCPB_MtrIndex_P 0;
BA_ "GenSigTimeoutTime_AGSM" SG_ 294 MCPB_MtrIndex_P 0;
BA_ "GenSigTimeoutTime_MCPB" SG_ 294 MCPB_MtrMaxCpbltyTrq_P 0;
BA_ "GenSigTimeoutTime_MCPA" SG_ 294 MCPB_MtrMaxCpbltyTrq_P 0;
BA_ "GenSigTimeoutTime_AGSM" SG_ 294 MCPB_MtrMaxCpbltyTrq_P 0;
BA_ "GenSigStartValue" SG_ 294 MCPB_MtrMaxCpbltyTrq_P 8184;
BA_ "GenSigTimeoutTime_MCPB" SG_ 294 MCPB_MtrMinCpbltyTrq_P 0;
BA_ "GenSigTimeoutTime_MCPA" SG_ 294 MCPB_MtrMinCpbltyTrq_P 0;
BA_ "GenSigTimeoutTime_AGSM" SG_ 294 MCPB_MtrMinCpbltyTrq_P 0;
BA_ "GenSigStartValue" SG_ 294 MCPB_MtrMinCpbltyTrq_P 8184;
BA_ "GenSigTimeoutTime_MCPB" SG_ 294 MCPB_RPM_P 0;
BA_ "GenSigTimeoutTime_MCPA" SG_ 294 MCPB_RPM_P 0;
BA_ "GenSigTimeoutTime_AGSM" SG_ 294 MCPB_RPM_P 0;
BA_ "GenSigStartValue" SG_ 294 MCPB_RPM_P 32768;
BA_ "GenSigTimeoutTime_MCPB" SG_ 294 MCPB_RPM_V_P 0;
BA_ "GenSigTimeoutTime_MCPA" SG_ 294 MCPB_RPM_V_P 0;
BA_ "GenSigTimeoutTime_AGSM" SG_ 294 MCPB_RPM_V_P 0;
BA_ "GenSigTimeoutTime_MCPB" SG_ 294 MCPB_Spd_Lim_P 0;
BA_ "GenSigTimeoutTime_MCPA" SG_ 294 MCPB_Spd_Lim_P 0;
BA_ "GenSigTimeoutTime_AGSM" SG_ 294 MCPB_Spd_Lim_P 0;
BA_ "GenSigTimeoutTime_MCPB" SG_ 294 MCPB_SPT_Stat_P 0;
BA_ "GenSigTimeoutTime_MCPA" SG_ 294 MCPB_SPT_Stat_P 0;
BA_ "GenSigTimeoutTime_AGSM" SG_ 294 MCPB_SPT_Stat_P 0;
BA_ "GenSigTimeoutTime_MCPB" SG_ 294 MCPB_TorqAchieved_AEMD_P 0;
BA_ "GenSigTimeoutTime_MCPA" SG_ 294 MCPB_TorqAchieved_AEMD_P 0;
BA_ "GenSigTimeoutTime_AGSM" SG_ 294 MCPB_TorqAchieved_AEMD_P 0;
BA_ "GenSigStartValue" SG_ 294 MCPB_TorqAchieved_AEMD_P 8184;
BA_ "GenSigTimeoutTime_MCPB" SG_ 294 MCPB_TorqAchieved_AEMD_V_P 0;
BA_ "GenSigTimeoutTime_MCPA" SG_ 294 MCPB_TorqAchieved_AEMD_V_P 0;
BA_ "GenSigTimeoutTime_AGSM" SG_ 294 MCPB_TorqAchieved_AEMD_V_P 0;
BA_ "GenSigTimeoutTime_MCPB" SG_ 294 MCPB_Torque_Achieved_P 0;
BA_ "GenSigTimeoutTime_MCPA" SG_ 294 MCPB_Torque_Achieved_P 0;
BA_ "GenSigTimeoutTime_AGSM" SG_ 294 MCPB_Torque_Achieved_P 0;
BA_ "GenSigStartValue" SG_ 294 MCPB_Torque_Achieved_P 8184;
BA_ "GenSigTimeoutTime_MCPB" SG_ 294 MCPB_Torque_Achieved_V_P 0;
BA_ "GenSigTimeoutTime_MCPA" SG_ 294 MCPB_Torque_Achieved_V_P 0;
BA_ "GenSigTimeoutTime_AGSM" SG_ 294 MCPB_Torque_Achieved_V_P 0;
BA_ "GenSigTimeoutTime_MCPB" SG_ 294 MPR_PosSensor_P 0;
BA_ "GenSigTimeoutTime_MCPA" SG_ 294 MPR_PosSensor_P 0;
BA_ "GenSigTimeoutTime_AGSM" SG_ 294 MPR_PosSensor_P 0;
BA_ "GenSigTimeoutTime_MCPB" SG_ 294 Plock_fdbk_sts_P 0;
BA_ "GenSigTimeoutTime_MCPA" SG_ 294 Plock_fdbk_sts_P 0;
BA_ "GenSigTimeoutTime_AGSM" SG_ 294 Plock_fdbk_sts_P 0;
BA_ "GenSigTimeoutTime_MCPB" SG_ 294 Plock_MotorPosSts_P 0;
BA_ "GenSigTimeoutTime_MCPA" SG_ 294 Plock_MotorPosSts_P 0;
BA_ "GenSigTimeoutTime_AGSM" SG_ 294 Plock_MotorPosSts_P 0;
BA_ "GenSigTimeoutTime_MCPB" SG_ 294 Plock_PosSensor_P 0;
BA_ "GenSigTimeoutTime_MCPA" SG_ 294 Plock_PosSensor_P 0;
BA_ "GenSigTimeoutTime_AGSM" SG_ 294 Plock_PosSensor_P 0;
BA_ "GenSigTimeoutTime_MCPB" SG_ 503 MCPA_DC_Current_V_P 0;
BA_ "GenSigTimeoutTime_MCPA" SG_ 503 MCPA_DC_Current_V_P 0;
BA_ "GenSigTimeoutTime_AGSM" SG_ 503 MCPA_DC_Current_V_P 0;
BA_ "GenSigTimeoutTime_MCPB" SG_ 503 MCPA_DC_Volt_V_P 0;
BA_ "GenSigTimeoutTime_MCPA" SG_ 503 MCPA_DC_Volt_V_P 0;
BA_ "GenSigTimeoutTime_AGSM" SG_ 503 MCPA_DC_Volt_V_P 0;
BA_ "GenSigTimeoutTime_MCPB" SG_ 503 MCPA_DC_Voltage_P 0;
BA_ "GenSigTimeoutTime_MCPA" SG_ 503 MCPA_DC_Voltage_P 0;
BA_ "GenSigTimeoutTime_AGSM" SG_ 503 MCPA_DC_Voltage_P 0;
BA_ "GenSigTimeoutTime_MCPB" SG_ 503 MCPA_DerateReason_P 0;
BA_ "GenSigTimeoutTime_MCPA" SG_ 503 MCPA_DerateReason_P 0;
BA_ "GenSigTimeoutTime_AGSM" SG_ 503 MCPA_DerateReason_P 0;
BA_ "GenSigTimeoutTime_MCPB" SG_ 294 MCPB_3PS_Pos_P 0;
BA_ "GenSigTimeoutTime_MCPA" SG_ 294 MCPB_3PS_Pos_P 0;
BA_ "GenSigTimeoutTime_AGSM" SG_ 294 MCPB_3PS_Pos_P 0;
BA_ "GenSigTimeoutTime_MCPB" SG_ 294 MCPB_6SO_Status_P 0;
BA_ "GenSigTimeoutTime_MCPA" SG_ 294 MCPB_6SO_Status_P 0;
BA_ "GenSigTimeoutTime_AGSM" SG_ 294 MCPB_6SO_Status_P 0;
BA_ "GenSigTimeoutTime_MCPB" SG_ 294 MCPB_AccelRawV_P 0;
BA_ "GenSigTimeoutTime_MCPA" SG_ 294 MCPB_AccelRawV_P 0;
BA_ "GenSigTimeoutTime_AGSM" SG_ 294 MCPB_AccelRawV_P 0;
BA_ "GenSigTimeoutTime_MCPB" SG_ 294 MCPB_CpbltySpdDivVolt_P 0;
BA_ "GenSigTimeoutTime_MCPA" SG_ 294 MCPB_CpbltySpdDivVolt_P 0;
BA_ "GenSigTimeoutTime_AGSM" SG_ 294 MCPB_CpbltySpdDivVolt_P 0;
BA_ "GenSigTimeoutTime_MCPB" SG_ 294 MCPB_DeratingFactor_P 0;
BA_ "GenSigTimeoutTime_MCPA" SG_ 294 MCPB_DeratingFactor_P 0;
BA_ "GenSigTimeoutTime_AGSM" SG_ 294 MCPB_DeratingFactor_P 0;
BA_ "GenSigTimeoutTime_MCPB" SG_ 294 MCPB_Dschrge_Status_P 0;
BA_ "GenSigTimeoutTime_MCPA" SG_ 294 MCPB_Dschrge_Status_P 0;
BA_ "GenSigTimeoutTime_AGSM" SG_ 294 MCPB_Dschrge_Status_P 0;
BA_ "GenSigTimeoutTime_MCPB" SG_ 294 MCPB_HV_CnctrOpn_Req_P 0;
BA_ "GenSigTimeoutTime_MCPA" SG_ 294 MCPB_HV_CnctrOpn_Req_P 0;
BA_ "GenSigTimeoutTime_AGSM" SG_ 294 MCPB_HV_CnctrOpn_Req_P 0;
BA_ "GenSigTimeoutTime_MCPB" SG_ 294 MCPB_InterlockSts_P 0;
BA_ "GenSigTimeoutTime_MCPA" SG_ 294 MCPB_InterlockSts_P 0;
BA_ "GenSigTimeoutTime_AGSM" SG_ 294 MCPB_InterlockSts_P 0;
BA_ "GenSigTimeoutTime_MCPB" SG_ 294 MCPB_Invrtr_State_P 0;
BA_ "GenSigTimeoutTime_MCPA" SG_ 294 MCPB_Invrtr_State_P 0;
BA_ "GenSigTimeoutTime_AGSM" SG_ 294 MCPB_Invrtr_State_P 0;
BA_ "GenSigTimeoutTime_MCPB" SG_ 294 MCPB_MaxTorq_P 0;
BA_ "GenSigTimeoutTime_MCPA" SG_ 294 MCPB_MaxTorq_P 0;
BA_ "GenSigTimeoutTime_AGSM" SG_ 294 MCPB_MaxTorq_P 0;
BA_ "GenSigStartValue" SG_ 294 MCPB_MaxTorq_P 8184;
BA_ "GenSigTimeoutTime_MCPB" SG_ 1065 MessageCounter_MCPB_OBD_DTC 0;
BA_ "GenSigTimeoutTime_MCPA" SG_ 1065 MessageCounter_MCPB_OBD_DTC 0;
BA_ "GenSigTimeoutTime_AGSM" SG_ 1065 MessageCounter_MCPB_OBD_DTC 0;
BA_ "GenSigTimeoutTime_MCPB" SG_ 1065 MCPB_DTC_Idx1 0;
BA_ "GenSigTimeoutTime_MCPA" SG_ 1065 MCPB_DTC_Idx1 0;
BA_ "GenSigTimeoutTime_AGSM" SG_ 1065 MCPB_DTC_Idx1 0;
BA_ "GenSigTimeoutTime_MCPB" SG_ 1065 MCPB_DTC_Idx2 0;
BA_ "GenSigTimeoutTime_MCPA" SG_ 1065 MCPB_DTC_Idx2 0;
BA_ "GenSigTimeoutTime_AGSM" SG_ 1065 MCPB_DTC_Idx2 0;
BA_ "GenSigTimeoutTime_MCPB" SG_ 1065 MCPB_DTC_Stat1 0;
BA_ "GenSigTimeoutTime_MCPA" SG_ 1065 MCPB_DTC_Stat1 0;
BA_ "GenSigTimeoutTime_AGSM" SG_ 1065 MCPB_DTC_Stat1 0;
BA_ "GenSigTimeoutTime_MCPB" SG_ 1065 MCPB_DTC_Stat2 0;
BA_ "GenSigTimeoutTime_MCPA" SG_ 1065 MCPB_DTC_Stat2 0;
BA_ "GenSigTimeoutTime_AGSM" SG_ 1065 MCPB_DTC_Stat2 0;
BA_ "GenSigTimeoutTime_MCPB" SG_ 1065 CRC_MCPB_OBD_DTC 0;
BA_ "GenSigTimeoutTime_MCPA" SG_ 1065 CRC_MCPB_OBD_DTC 0;
BA_ "GenSigTimeoutTime_AGSM" SG_ 1065 CRC_MCPB_OBD_DTC 0;
BA_ "GenSigTimeoutTime_MCPB" SG_ 1065 MCPB_Cal_ID_Idx 0;
BA_ "GenSigTimeoutTime_MCPA" SG_ 1065 MCPB_Cal_ID_Idx 0;
BA_ "GenSigTimeoutTime_AGSM" SG_ 1065 MCPB_Cal_ID_Idx 0;
BA_ "GenSigTimeoutTime_MCPB" SG_ 1065 MCPB_CalChar 0;
BA_ "GenSigTimeoutTime_MCPA" SG_ 1065 MCPB_CalChar 0;
BA_ "GenSigTimeoutTime_AGSM" SG_ 1065 MCPB_CalChar 0;
BA_ "GenSigTimeoutTime_MCPB" SG_ 503 MCPA_Service_Lamp_Request_P 0;
BA_ "GenSigTimeoutTime_MCPA" SG_ 503 MCPA_Service_Lamp_Request_P 0;
BA_ "GenSigTimeoutTime_AGSM" SG_ 503 MCPA_Service_Lamp_Request_P 0;
BA_ "GenSigTimeoutTime_MCPA" SG_ 503 MCPA_Rotor_Temperature_P 0;
BA_ "GenSigTimeoutTime_AGSM" SG_ 503 MCPA_Rotor_Temperature_P 0;
BA_ "GenSigStartValue" SG_ 503 MCPA_Rotor_Temperature_P 255;
BA_ "GenSigTimeoutTime_MCPB" SG_ 503 MCPA_Rotor_Temperature_P 0;
BA_ "GenSigTimeoutTime_MCPB" SG_ 503 MCPA_PIM_DC_Side_Busbar_Temp_P 0;
BA_ "GenSigTimeoutTime_MCPA" SG_ 503 MCPA_PIM_DC_Side_Busbar_Temp_P 0;
BA_ "GenSigTimeoutTime_AGSM" SG_ 503 MCPA_PIM_DC_Side_Busbar_Temp_P 0;
BA_ "GenSigTimeoutTime_MCPB" SG_ 503 CLrDiagInfo_MCPA_P 0;
BA_ "GenSigTimeoutTime_MCPA" SG_ 503 CLrDiagInfo_MCPA_P 0;
BA_ "GenSigTimeoutTime_AGSM" SG_ 503 CLrDiagInfo_MCPA_P 0;
BA_ "GenSigTimeoutTime_MCPB" SG_ 293 MCPA_AC_Isolation_Status_P 0;
BA_ "GenSigTimeoutTime_MCPA" SG_ 293 MCPA_AC_Isolation_Status_P 0;
BA_ "GenSigTimeoutTime_AGSM" SG_ 293 MCPA_AC_Isolation_Status_P 0;
BA_ "GenSigTimeoutTime_MCPB" SG_ 293 MCPA_Temp_P 0;
BA_ "GenSigTimeoutTime_MCPA" SG_ 293 MCPA_Temp_P 0;
BA_ "GenSigTimeoutTime_AGSM" SG_ 293 MCPA_Temp_P 0;
BA_ "GenSigStartValue" SG_ 293 MCPA_Temp_P 40;
BA_ "GenSigTimeoutTime_MCPB" SG_ 503 MCPA_Control_Board_Temperature_P 0;
BA_ "GenSigTimeoutTime_MCPA" SG_ 503 MCPA_Control_Board_Temperature_P 0;
BA_ "GenSigTimeoutTime_AGSM" SG_ 503 MCPA_Control_Board_Temperature_P 0;
BA_ "GenSigStartValue" SG_ 503 MCPA_Control_Board_Temperature_P 255;
BA_ "GenSigTimeoutTime_MCPB" SG_ 1057 MessageCounter_MCPA_OBD_DTC 0;
BA_ "GenSigTimeoutTime_MCPA" SG_ 1057 MessageCounter_MCPA_OBD_DTC 0;
BA_ "GenSigTimeoutTime_AGSM" SG_ 1057 MessageCounter_MCPA_OBD_DTC 0;
BA_ "GenSigTimeoutTime_MCPB" SG_ 1057 MCPA_DTC_Idx1 0;
BA_ "GenSigTimeoutTime_MCPA" SG_ 1057 MCPA_DTC_Idx1 0;
BA_ "GenSigTimeoutTime_AGSM" SG_ 1057 MCPA_DTC_Idx1 0;
BA_ "GenSigTimeoutTime_MCPB" SG_ 1057 MCPA_DTC_Idx2 0;
BA_ "GenSigTimeoutTime_MCPA" SG_ 1057 MCPA_DTC_Idx2 0;
BA_ "GenSigTimeoutTime_AGSM" SG_ 1057 MCPA_DTC_Idx2 0;
BA_ "GenSigTimeoutTime_MCPB" SG_ 1057 MCPA_DTC_Stat1 0;
BA_ "GenSigTimeoutTime_MCPA" SG_ 1057 MCPA_DTC_Stat1 0;
BA_ "GenSigTimeoutTime_AGSM" SG_ 1057 MCPA_DTC_Stat1 0;
BA_ "GenSigTimeoutTime_MCPB" SG_ 1057 MCPA_DTC_Stat2 0;
BA_ "GenSigTimeoutTime_MCPA" SG_ 1057 MCPA_DTC_Stat2 0;
BA_ "GenSigTimeoutTime_AGSM" SG_ 1057 MCPA_DTC_Stat2 0;
BA_ "GenSigTimeoutTime_EVCU2" SG_ 1829 TotalOdometer 0;
BA_ "GenSigTimeoutTime_AGSM" SG_ 1829 TotalOdometer 0;
BA_ "GenSigTimeoutTime_MCPB" SG_ 503 MCPA_CoolantTemp_P 0;
BA_ "GenSigTimeoutTime_MCPA" SG_ 503 MCPA_CoolantTemp_P 0;
BA_ "GenSigTimeoutTime_AGSM" SG_ 503 MCPA_CoolantTemp_P 0;
BA_ "GenSigTimeoutTime_MCPB" SG_ 503 MCPA_DC_Current_P 0;
BA_ "GenSigTimeoutTime_MCPA" SG_ 503 MCPA_DC_Current_P 0;
BA_ "GenSigTimeoutTime_AGSM" SG_ 503 MCPA_DC_Current_P 0;
BA_ "GenSigStartValue" SG_ 503 MCPA_DC_Current_P 16384;
BA_ "GenSigTimeoutTime_MCPB" SG_ 293 MCPA_Invrtr_State_P 0;
BA_ "GenSigTimeoutTime_MCPA" SG_ 293 MCPA_Invrtr_State_P 0;
BA_ "GenSigTimeoutTime_AGSM" SG_ 293 MCPA_Invrtr_State_P 0;
BA_ "GenSigTimeoutTime_MCPB" SG_ 293 MCPA_MaxTorq_P 0;
BA_ "GenSigTimeoutTime_MCPA" SG_ 293 MCPA_MaxTorq_P 0;
BA_ "GenSigTimeoutTime_AGSM" SG_ 293 MCPA_MaxTorq_P 0;
BA_ "GenSigStartValue" SG_ 293 MCPA_MaxTorq_P 8184;
BA_ "GenSigTimeoutTime_MCPB" SG_ 293 MCPA_MinTorq_P 0;
BA_ "GenSigTimeoutTime_MCPA" SG_ 293 MCPA_MinTorq_P 0;
BA_ "GenSigTimeoutTime_AGSM" SG_ 293 MCPA_MinTorq_P 0;
BA_ "GenSigStartValue" SG_ 293 MCPA_MinTorq_P 8184;
BA_ "GenSigTimeoutTime_MCPB" SG_ 293 MCPA_MtrIndex_P 0;
BA_ "GenSigTimeoutTime_MCPA" SG_ 293 MCPA_MtrIndex_P 0;
BA_ "GenSigTimeoutTime_AGSM" SG_ 293 MCPA_MtrIndex_P 0;
BA_ "GenSigTimeoutTime_MCPB" SG_ 293 MCPA_MtrMaxCpbltyTrq_P 0;
BA_ "GenSigTimeoutTime_MCPA" SG_ 293 MCPA_MtrMaxCpbltyTrq_P 0;
BA_ "GenSigTimeoutTime_AGSM" SG_ 293 MCPA_MtrMaxCpbltyTrq_P 0;
BA_ "GenSigStartValue" SG_ 293 MCPA_MtrMaxCpbltyTrq_P 8184;
BA_ "GenSigTimeoutTime_MCPB" SG_ 293 MCPA_MtrMinCpbltyTrq_P 0;
BA_ "GenSigTimeoutTime_MCPA" SG_ 293 MCPA_MtrMinCpbltyTrq_P 0;
BA_ "GenSigTimeoutTime_AGSM" SG_ 293 MCPA_MtrMinCpbltyTrq_P 0;
BA_ "GenSigStartValue" SG_ 293 MCPA_MtrMinCpbltyTrq_P 8184;
BA_ "GenSigTimeoutTime_MCPB" SG_ 293 MCPA_RPM_P 0;
BA_ "GenSigTimeoutTime_MCPA" SG_ 293 MCPA_RPM_P 0;
BA_ "GenSigTimeoutTime_AGSM" SG_ 293 MCPA_RPM_P 0;
BA_ "GenSigStartValue" SG_ 293 MCPA_RPM_P 32768;
BA_ "GenSigTimeoutTime_MCPB" SG_ 293 MCPA_RPM_V_P 0;
BA_ "GenSigTimeoutTime_MCPA" SG_ 293 MCPA_RPM_V_P 0;
BA_ "GenSigTimeoutTime_AGSM" SG_ 293 MCPA_RPM_V_P 0;
BA_ "GenSigTimeoutTime_MCPB" SG_ 293 MCPA_Spd_Lim_P 0;
BA_ "GenSigTimeoutTime_MCPA" SG_ 293 MCPA_Spd_Lim_P 0;
BA_ "GenSigTimeoutTime_AGSM" SG_ 293 MCPA_Spd_Lim_P 0;
BA_ "GenSigStartValue" SG_ 293 MCPA_Spd_Lim_P 32767;
BA_ "GenSigTimeoutTime_MCPB" SG_ 293 MCPA_SPT_Stat_P 0;
BA_ "GenSigTimeoutTime_MCPA" SG_ 293 MCPA_SPT_Stat_P 0;
BA_ "GenSigTimeoutTime_AGSM" SG_ 293 MCPA_SPT_Stat_P 0;
BA_ "GenSigTimeoutTime_MCPB" SG_ 293 MCPA_TorqAchieved_AEMD_P 0;
BA_ "GenSigTimeoutTime_MCPA" SG_ 293 MCPA_TorqAchieved_AEMD_P 0;
BA_ "GenSigTimeoutTime_AGSM" SG_ 293 MCPA_TorqAchieved_AEMD_P 0;
BA_ "GenSigStartValue" SG_ 293 MCPA_TorqAchieved_AEMD_P 8184;
BA_ "GenSigTimeoutTime_MCPB" SG_ 293 MCPA_TorqAchieved_AEMD_V_P 0;
BA_ "GenSigTimeoutTime_MCPA" SG_ 293 MCPA_TorqAchieved_AEMD_V_P 0;
BA_ "GenSigTimeoutTime_AGSM" SG_ 293 MCPA_TorqAchieved_AEMD_V_P 0;
BA_ "GenSigTimeoutTime_MCPB" SG_ 293 MCPA_Torque_Achieved_P 0;
BA_ "GenSigTimeoutTime_MCPA" SG_ 293 MCPA_Torque_Achieved_P 0;
BA_ "GenSigTimeoutTime_AGSM" SG_ 293 MCPA_Torque_Achieved_P 0;
BA_ "GenSigStartValue" SG_ 293 MCPA_Torque_Achieved_P 8184;
BA_ "GenSigTimeoutTime_MCPB" SG_ 293 MCPA_Torque_Achieved_V_P 0;
BA_ "GenSigTimeoutTime_MCPA" SG_ 293 MCPA_Torque_Achieved_V_P 0;
BA_ "GenSigTimeoutTime_AGSM" SG_ 293 MCPA_Torque_Achieved_V_P 0;
BA_ "GenSigTimeoutTime_MCPB" SG_ 503 CRC_MCPA_STATUS 0;
BA_ "GenSigTimeoutTime_MCPA" SG_ 503 CRC_MCPA_STATUS 0;
BA_ "GenSigTimeoutTime_AGSM" SG_ 503 CRC_MCPA_STATUS 0;
BA_ "GenSigTimeoutTime_MCPB" SG_ 503 MC_MCPA_STATUS 0;
BA_ "GenSigTimeoutTime_MCPA" SG_ 503 MC_MCPA_STATUS 0;
BA_ "GenSigTimeoutTime_AGSM" SG_ 503 MC_MCPA_STATUS 0;
BA_ "GenSigTimeoutTime_MCPB" SG_ 1057 CRC_MCPA_OBD_DTC 0;
BA_ "GenSigTimeoutTime_MCPA" SG_ 1057 CRC_MCPA_OBD_DTC 0;
BA_ "GenSigTimeoutTime_AGSM" SG_ 1057 CRC_MCPA_OBD_DTC 0;
BA_ "GenSigTimeoutTime_MCPB" SG_ 1057 MCPA_Cal_ID_Idx 0;
BA_ "GenSigTimeoutTime_MCPA" SG_ 1057 MCPA_Cal_ID_Idx 0;
BA_ "GenSigTimeoutTime_AGSM" SG_ 1057 MCPA_Cal_ID_Idx 0;
BA_ "GenSigTimeoutTime_MCPB" SG_ 1057 MCPA_CalChar 0;
BA_ "GenSigTimeoutTime_MCPA" SG_ 1057 MCPA_CalChar 0;
BA_ "GenSigTimeoutTime_AGSM" SG_ 1057 MCPA_CalChar 0;
BA_ "GenSigTimeoutTime_MCPB" SG_ 293 MCPA_AccelRaw_P 0;
BA_ "GenSigTimeoutTime_MCPA" SG_ 293 MCPA_AccelRaw_P 0;
BA_ "GenSigTimeoutTime_AGSM" SG_ 293 MCPA_AccelRaw_P 0;
BA_ "GenSigStartValue" SG_ 293 MCPA_AccelRaw_P 32768;
BA_ "GenSigTimeoutTime_MCPB" SG_ 293 CRC_MCPA_PROPULSION 0;
BA_ "GenSigTimeoutTime_MCPA" SG_ 293 CRC_MCPA_PROPULSION 0;
BA_ "GenSigTimeoutTime_AGSM" SG_ 293 CRC_MCPA_PROPULSION 0;
BA_ "GenSigTimeoutTime_MCPB" SG_ 293 MC_MCPA_PROPULSION 0;
BA_ "GenSigTimeoutTime_MCPA" SG_ 293 MC_MCPA_PROPULSION 0;
BA_ "GenSigTimeoutTime_AGSM" SG_ 293 MC_MCPA_PROPULSION 0;
BA_ "GenSigTimeoutTime_MCPA" SG_ 297 SpdGrdtLim_MCPB_P 0;
BA_ "GenSigTimeoutTime_EVCU2" SG_ 297 SpdGrdtLim_MCPB_P 0;
BA_ "GenSigTimeoutTime_AGSM" SG_ 297 SpdGrdtLim_MCPB_P 0;
BA_ "GenSigTimeoutTime_MCPB" SG_ 297 TqGrdtLim_MCPA_P 0;
BA_ "GenSigTimeoutTime_EVCU2" SG_ 297 TqGrdtLim_MCPA_P 0;
BA_ "GenSigTimeoutTime_AGSM" SG_ 297 TqGrdtLim_MCPA_P 0;
BA_ "GenSigTimeoutTime_MCPA" SG_ 297 TqGrdtLim_MCPB_P 0;
BA_ "GenSigTimeoutTime_EVCU2" SG_ 297 TqGrdtLim_MCPB_P 0;
BA_ "GenSigTimeoutTime_AGSM" SG_ 297 TqGrdtLim_MCPB_P 0;
BA_ "GenSigTimeoutTime_MCPB" SG_ 297 UDCMax_Unlim_MCPA_P 0;
BA_ "GenSigTimeoutTime_EVCU2" SG_ 297 UDCMax_Unlim_MCPA_P 0;
BA_ "GenSigTimeoutTime_AGSM" SG_ 297 UDCMax_Unlim_MCPA_P 0;
BA_ "GenSigTimeoutTime_MCPA" SG_ 297 UDCMax_Unlim_MCPB_P 0;
BA_ "GenSigTimeoutTime_EVCU2" SG_ 297 UDCMax_Unlim_MCPB_P 0;
BA_ "GenSigTimeoutTime_AGSM" SG_ 297 UDCMax_Unlim_MCPB_P 0;
BA_ "GenSigTimeoutTime_MCPB" SG_ 297 UDCMin_Unlim_MCPA_P 0;
BA_ "GenSigTimeoutTime_EVCU2" SG_ 297 UDCMin_Unlim_MCPA_P 0;
BA_ "GenSigTimeoutTime_AGSM" SG_ 297 UDCMin_Unlim_MCPA_P 0;
BA_ "GenSigTimeoutTime_MCPA" SG_ 297 UDCMin_Unlim_MCPB_P 0;
BA_ "GenSigTimeoutTime_EVCU2" SG_ 297 UDCMin_Unlim_MCPB_P 0;
BA_ "GenSigTimeoutTime_AGSM" SG_ 297 UDCMin_Unlim_MCPB_P 0;
BA_ "GenSigTimeoutTime_MCPB" SG_ 293 MCPA_3PS_Pos_P 0;
BA_ "GenSigTimeoutTime_MCPA" SG_ 293 MCPA_3PS_Pos_P 0;
BA_ "GenSigTimeoutTime_AGSM" SG_ 293 MCPA_3PS_Pos_P 0;
BA_ "GenSigTimeoutTime_MCPB" SG_ 293 MCPA_6SO_Status_P 0;
BA_ "GenSigTimeoutTime_MCPA" SG_ 293 MCPA_6SO_Status_P 0;
BA_ "GenSigTimeoutTime_AGSM" SG_ 293 MCPA_6SO_Status_P 0;
BA_ "GenSigTimeoutTime_MCPB" SG_ 293 MCPA_AccelRawV_P 0;
BA_ "GenSigTimeoutTime_MCPA" SG_ 293 MCPA_AccelRawV_P 0;
BA_ "GenSigTimeoutTime_AGSM" SG_ 293 MCPA_AccelRawV_P 0;
BA_ "GenSigTimeoutTime_MCPB" SG_ 293 MCPA_CpbltySpdDivVolt_P 0;
BA_ "GenSigTimeoutTime_MCPA" SG_ 293 MCPA_CpbltySpdDivVolt_P 0;
BA_ "GenSigTimeoutTime_AGSM" SG_ 293 MCPA_CpbltySpdDivVolt_P 0;
BA_ "GenSigTimeoutTime_MCPB" SG_ 293 MCPA_DeratingFactor_P 0;
BA_ "GenSigTimeoutTime_MCPA" SG_ 293 MCPA_DeratingFactor_P 0;
BA_ "GenSigTimeoutTime_AGSM" SG_ 293 MCPA_DeratingFactor_P 0;
BA_ "GenSigTimeoutTime_MCPB" SG_ 293 MCPA_Dschrge_Status_P 0;
BA_ "GenSigTimeoutTime_MCPA" SG_ 293 MCPA_Dschrge_Status_P 0;
BA_ "GenSigTimeoutTime_AGSM" SG_ 293 MCPA_Dschrge_Status_P 0;
BA_ "GenSigTimeoutTime_MCPB" SG_ 293 MCPA_HV_CnctrOpn_Req_P 0;
BA_ "GenSigTimeoutTime_MCPA" SG_ 293 MCPA_HV_CnctrOpn_Req_P 0;
BA_ "GenSigTimeoutTime_AGSM" SG_ 293 MCPA_HV_CnctrOpn_Req_P 0;
BA_ "GenSigTimeoutTime_MCPB" SG_ 293 MCPA_InterlockSts_P 0;
BA_ "GenSigTimeoutTime_MCPA" SG_ 293 MCPA_InterlockSts_P 0;
BA_ "GenSigTimeoutTime_AGSM" SG_ 293 MCPA_InterlockSts_P 0;
BA_ "GenSigTimeoutTime_MCPB" SG_ 297 SpdGrdtLim_MCPA_P 0;
BA_ "GenSigTimeoutTime_EVCU2" SG_ 297 SpdGrdtLim_MCPA_P 0;
BA_ "GenSigTimeoutTime_AGSM" SG_ 297 SpdGrdtLim_MCPA_P 0;
BA_ "GenSigTimeoutTime_MCPA" SG_ 296 ModeCommand_MCPB_P 0;
BA_ "GenSigTimeoutTime_EVCU2" SG_ 296 ModeCommand_MCPB_P 0;
BA_ "GenSigTimeoutTime_AGSM" SG_ 296 ModeCommand_MCPB_P 0;
BA_ "GenSigTimeoutTime_MCPB" SG_ 296 Mtr_6SO_Request_MCPA_P 0;
BA_ "GenSigTimeoutTime_EVCU2" SG_ 296 Mtr_6SO_Request_MCPA_P 0;
BA_ "GenSigTimeoutTime_AGSM" SG_ 296 Mtr_6SO_Request_MCPA_P 0;
BA_ "GenSigTimeoutTime_MCPA" SG_ 296 Mtr_6SO_Request_MCPB_P 0;
BA_ "GenSigTimeoutTime_EVCU2" SG_ 296 Mtr_6SO_Request_MCPB_P 0;
BA_ "GenSigTimeoutTime_AGSM" SG_ 296 Mtr_6SO_Request_MCPB_P 0;
BA_ "GenSigTimeoutTime_MCPA" SG_ 296 ParkCmd_PT_P 0;
BA_ "GenSigTimeoutTime_EVCU2" SG_ 296 ParkCmd_PT_P 0;
BA_ "GenSigTimeoutTime_AGSM" SG_ 296 ParkCmd_PT_P 0;
BA_ "GenSigTimeoutTime_MCPA" SG_ 296 ShiftLeverPosition_P 0;
BA_ "GenSigTimeoutTime_EVCU2" SG_ 296 ShiftLeverPosition_P 0;
BA_ "GenSigTimeoutTime_AGSM" SG_ 296 ShiftLeverPosition_P 0;
BA_ "GenSigTimeoutTime_MCPB" SG_ 296 TargetMotorRPM_MCPA_P 0;
BA_ "GenSigTimeoutTime_EVCU2" SG_ 296 TargetMotorRPM_MCPA_P 0;
BA_ "GenSigTimeoutTime_AGSM" SG_ 296 TargetMotorRPM_MCPA_P 0;
BA_ "GenSigStartValue" SG_ 296 TargetMotorRPM_MCPA_P 32768;
BA_ "GenSigTimeoutTime_MCPA" SG_ 296 TargetMotorRPM_MCPB_P 0;
BA_ "GenSigTimeoutTime_EVCU2" SG_ 296 TargetMotorRPM_MCPB_P 0;
BA_ "GenSigTimeoutTime_AGSM" SG_ 296 TargetMotorRPM_MCPB_P 0;
BA_ "GenSigStartValue" SG_ 296 TargetMotorRPM_MCPB_P 32768;
BA_ "GenSigTimeoutTime_MCPB" SG_ 296 TorqueCommand_MCPA_P 0;
BA_ "GenSigTimeoutTime_EVCU2" SG_ 296 TorqueCommand_MCPA_P 0;
BA_ "GenSigTimeoutTime_AGSM" SG_ 296 TorqueCommand_MCPA_P 0;
BA_ "GenSigStartValue" SG_ 296 TorqueCommand_MCPA_P 8184;
BA_ "GenSigTimeoutTime_MCPA" SG_ 296 TorqueCommand_MCPB_P 0;
BA_ "GenSigTimeoutTime_EVCU2" SG_ 296 TorqueCommand_MCPB_P 0;
BA_ "GenSigTimeoutTime_AGSM" SG_ 296 TorqueCommand_MCPB_P 0;
BA_ "GenSigStartValue" SG_ 296 TorqueCommand_MCPB_P 8184;
BA_ "GenSigTimeoutTime_EVCU2" SG_ 296 VehicleSpeedVSOSig_P 0;
BA_ "GenSigTimeoutTime_AGSM" SG_ 296 VehicleSpeedVSOSig_P 0;
BA_ "GenSigTimeoutTime_EVCU2" SG_ 297 CRC_INVTARGET_PROPULSION2 0;
BA_ "GenSigTimeoutTime_AGSM" SG_ 297 CRC_INVTARGET_PROPULSION2 0;
BA_ "GenSigTimeoutTime_MCPB" SG_ 297 EVCU_MotorA_Speed 0;
BA_ "GenSigTimeoutTime_EVCU2" SG_ 297 EVCU_MotorA_Speed 0;
BA_ "GenSigTimeoutTime_AGSM" SG_ 297 EVCU_MotorA_Speed 0;
BA_ "GenSigStartValue" SG_ 297 EVCU_MotorA_Speed 32768;
BA_ "GenSigTimeoutTime_MCPA" SG_ 297 EVCU_MotorB_Speed 0;
BA_ "GenSigTimeoutTime_EVCU2" SG_ 297 EVCU_MotorB_Speed 0;
BA_ "GenSigTimeoutTime_AGSM" SG_ 297 EVCU_MotorB_Speed 0;
BA_ "GenSigStartValue" SG_ 297 EVCU_MotorB_Speed 32768;
BA_ "GenSigTimeoutTime_EVCU2" SG_ 297 MC_INVTARGET_PROPULSION2 0;
BA_ "GenSigTimeoutTime_AGSM" SG_ 297 MC_INVTARGET_PROPULSION2 0;
BA_ "GenSigTimeoutTime_MCPB" SG_ 297 Pwr_Electr_Loop_FlwRate_MCPA_P 0;
BA_ "GenSigTimeoutTime_EVCU2" SG_ 297 Pwr_Electr_Loop_FlwRate_MCPA_P 0;
BA_ "GenSigTimeoutTime_AGSM" SG_ 297 Pwr_Electr_Loop_FlwRate_MCPA_P 0;
BA_ "GenSigTimeoutTime_MCPA" SG_ 297 Pwr_Electr_Loop_FlwRate_MCPB_P 0;
BA_ "GenSigTimeoutTime_EVCU2" SG_ 297 Pwr_Electr_Loop_FlwRate_MCPB_P 0;
BA_ "GenSigTimeoutTime_AGSM" SG_ 297 Pwr_Electr_Loop_FlwRate_MCPB_P 0;
BA_ "GenSigTimeoutTime_MCPB" SG_ 296 AEMD_Sclr_Gn_MCPA_P 0;
BA_ "GenSigTimeoutTime_EVCU2" SG_ 296 AEMD_Sclr_Gn_MCPA_P 0;
BA_ "GenSigTimeoutTime_AGSM" SG_ 296 AEMD_Sclr_Gn_MCPA_P 0;
BA_ "GenSigTimeoutTime_MCPA" SG_ 296 AEMD_Sclr_Gn_MCPB_P 0;
BA_ "GenSigTimeoutTime_EVCU2" SG_ 296 AEMD_Sclr_Gn_MCPB_P 0;
BA_ "GenSigTimeoutTime_AGSM" SG_ 296 AEMD_Sclr_Gn_MCPB_P 0;
BA_ "GenSigTimeoutTime_MCPB" SG_ 296 AEMD_Cutoff_FreqHigh_MCPA_P 0;
BA_ "GenSigTimeoutTime_EVCU2" SG_ 296 AEMD_Cutoff_FreqHigh_MCPA_P 0;
BA_ "GenSigTimeoutTime_AGSM" SG_ 296 AEMD_Cutoff_FreqHigh_MCPA_P 0;
BA_ "GenSigTimeoutTime_MCPA" SG_ 296 AEMD_Cutoff_FreqHigh_MCPB_P 0;
BA_ "GenSigTimeoutTime_EVCU2" SG_ 296 AEMD_Cutoff_FreqHigh_MCPB_P 0;
BA_ "GenSigTimeoutTime_AGSM" SG_ 296 AEMD_Cutoff_FreqHigh_MCPB_P 0;
BA_ "GenSigTimeoutTime_MCPB" SG_ 296 AEMD_Cutoff_FreqLow_MCPA_P 0;
BA_ "GenSigTimeoutTime_EVCU2" SG_ 296 AEMD_Cutoff_FreqLow_MCPA_P 0;
BA_ "GenSigTimeoutTime_AGSM" SG_ 296 AEMD_Cutoff_FreqLow_MCPA_P 0;
BA_ "GenSigTimeoutTime_MCPA" SG_ 296 AEMD_Cutoff_FreqLow_MCPB_P 0;
BA_ "GenSigTimeoutTime_EVCU2" SG_ 296 AEMD_Cutoff_FreqLow_MCPB_P 0;
BA_ "GenSigTimeoutTime_AGSM" SG_ 296 AEMD_Cutoff_FreqLow_MCPB_P 0;
BA_ "GenSigTimeoutTime_MCPB" SG_ 296 AEMD_MaxOffset_MCPA_P 0;
BA_ "GenSigTimeoutTime_EVCU2" SG_ 296 AEMD_MaxOffset_MCPA_P 0;
BA_ "GenSigTimeoutTime_AGSM" SG_ 296 AEMD_MaxOffset_MCPA_P 0;
BA_ "GenSigStartValue" SG_ 296 AEMD_MaxOffset_MCPA_P 8184;
BA_ "GenSigTimeoutTime_MCPA" SG_ 296 AEMD_MaxOffset_MCPB_P 0;
BA_ "GenSigTimeoutTime_EVCU2" SG_ 296 AEMD_MaxOffset_MCPB_P 0;
BA_ "GenSigTimeoutTime_AGSM" SG_ 296 AEMD_MaxOffset_MCPB_P 0;
BA_ "GenSigStartValue" SG_ 296 AEMD_MaxOffset_MCPB_P 8184;
BA_ "GenSigTimeoutTime_MCPB" SG_ 296 AEMD_MinOffset_MCPA_P 0;
BA_ "GenSigTimeoutTime_EVCU2" SG_ 296 AEMD_MinOffset_MCPA_P 0;
BA_ "GenSigTimeoutTime_AGSM" SG_ 296 AEMD_MinOffset_MCPA_P 0;
BA_ "GenSigStartValue" SG_ 296 AEMD_MinOffset_MCPA_P 8184;
BA_ "GenSigTimeoutTime_MCPA" SG_ 296 AEMD_MinOffset_MCPB_P 0;
BA_ "GenSigTimeoutTime_EVCU2" SG_ 296 AEMD_MinOffset_MCPB_P 0;
BA_ "GenSigTimeoutTime_AGSM" SG_ 296 AEMD_MinOffset_MCPB_P 0;
BA_ "GenSigStartValue" SG_ 296 AEMD_MinOffset_MCPB_P 8184;
BA_ "GenSigTimeoutTime_EVCU2" SG_ 296 BPCM_HV_Trac_Main_Contac_Sts_P 0;
BA_ "GenSigTimeoutTime_AGSM" SG_ 296 BPCM_HV_Trac_Main_Contac_Sts_P 0;
BA_ "GenSigTimeoutTime_EVCU2" SG_ 296 BPCM_HV_TractionBusVoltage_P 0;
BA_ "GenSigTimeoutTime_AGSM" SG_ 296 BPCM_HV_TractionBusVoltage_P 0;
BA_ "GenSigTimeoutTime_EVCU2" SG_ 296 CmdIgnSts_P 0;
BA_ "GenSigTimeoutTime_AGSM" SG_ 296 CmdIgnSts_P 0;
BA_ "GenSigTimeoutTime_EVCU2" SG_ 296 CRC_INVTARGET_PROPULSION1 0;
BA_ "GenSigTimeoutTime_AGSM" SG_ 296 CRC_INVTARGET_PROPULSION1 0;
BA_ "GenSigTimeoutTime_EVCU2" SG_ 296 MC_INVTARGET_PROPULSION1 0;
BA_ "GenSigTimeoutTime_AGSM" SG_ 296 MC_INVTARGET_PROPULSION1 0;
BA_ "GenSigTimeoutTime_MCPB" SG_ 296 ModeCommand_MCPA_P 0;
BA_ "GenSigTimeoutTime_EVCU2" SG_ 296 ModeCommand_MCPA_P 0;
BA_ "GenSigTimeoutTime_AGSM" SG_ 296 ModeCommand_MCPA_P 0;
BA_ "GenSigTimeoutTime_MCPA" SG_ 1032 EOPB_OIL_TEMP 0;
BA_ "GenSigTimeoutTime_EVCU2" SG_ 1032 EOPB_OIL_TEMP 0;
BA_ "GenSigTimeoutTime_AGSM" SG_ 1032 EOPB_OIL_TEMP 0;
BA_ "GenSigTimeoutTime_MCPB" SG_ 1032 EOPA_OIL_FlwRate 0;
BA_ "GenSigTimeoutTime_EVCU2" SG_ 1032 EOPA_OIL_FlwRate 0;
BA_ "GenSigTimeoutTime_AGSM" SG_ 1032 EOPA_OIL_FlwRate 0;
BA_ "GenSigTimeoutTime_MCPB" SG_ 1032 EOPA_OIL_TEMP 0;
BA_ "GenSigTimeoutTime_EVCU2" SG_ 1032 EOPA_OIL_TEMP 0;
BA_ "GenSigTimeoutTime_AGSM" SG_ 1032 EOPA_OIL_TEMP 0;
BA_ "GenSigTimeoutTime_MCPA" SG_ 1032 EOPB_OIL_FlwRate 0;
BA_ "GenSigTimeoutTime_EVCU2" SG_ 1032 EOPB_OIL_FlwRate 0;
BA_ "GenSigTimeoutTime_AGSM" SG_ 1032 EOPB_OIL_FlwRate 0;
BA_ "GenSigTimeoutTime_EVCU2" SG_ 1626 IMPACTConfirm 0;
BA_ "GenSigTimeoutTime_AGSM" SG_ 1626 IMPACTConfirm 0;
BA_ "GenSigSendType" SG_ 1626 IMPACTConfirm 5;
BA_ "GenSigInactiveValue" SG_ 1626 IMPACTConfirm 1;
BA_ "GenSigStartValue" SG_ 1626 IMPACTConfirm 1;
BA_ "GenSigTimeoutTime_EVCU2" SG_ 1626 IMPACTCommand 0;
BA_ "GenSigTimeoutTime_AGSM" SG_ 1626 IMPACTCommand 0;
BA_ "GenSigSendType" SG_ 1626 IMPACTCommand 5;
BA_ "GenSigTimeoutTime_MCPB" SG_ 2564502513 N_PDU 0;
BA_ "GenSigTimeoutTime_MCPA" SG_ 2564502513 N_PDU 0;
BA_ "GenSigTimeoutTime_EVCU2" SG_ 2564502513 N_PDU 0;
BA_ "GenSigTimeoutTime_AGSM" SG_ 2564502513 N_PDU 0;
BA_ "GenSigTimeoutTime_MCPB" SG_ 126 N_PDU 0;
BA_ "GenSigTimeoutTime_EVCU2" SG_ 126 N_PDU 0;
BA_ "GenSigTimeoutTime_AGSM" SG_ 126 N_PDU 0;
BA_ "GenSigTimeoutTime_MCPB" SG_ 123 N_PDU 0;
BA_ "GenSigTimeoutTime_MCPA" SG_ 123 N_PDU 0;
BA_ "GenSigTimeoutTime_AGSM" SG_ 123 N_PDU 0;
BA_ "GenSigTimeoutTime_MCPA" SG_ 127 N_PDU 0;
BA_ "GenSigTimeoutTime_EVCU2" SG_ 127 N_PDU 0;
BA_ "GenSigTimeoutTime_AGSM" SG_ 127 N_PDU 0;
BA_ "GenSigTimeoutTime_MCPB" SG_ 124 N_PDU 0;
BA_ "GenSigTimeoutTime_MCPA" SG_ 124 N_PDU 0;
BA_ "GenSigTimeoutTime_AGSM" SG_ 124 N_PDU 0;
BA_ "GenSigTimeoutTime_MCPB" SG_ 276 CRC_HYBRID_POWERTRAIN1 0;
BA_ "GenSigTimeoutTime_MCPA" SG_ 276 CRC_HYBRID_POWERTRAIN1 0;
BA_ "GenSigTimeoutTime_EVCU2" SG_ 276 CRC_HYBRID_POWERTRAIN1 0;
BA_ "GenSigTimeoutTime_AGSM" SG_ 276 CRC_HYBRID_POWERTRAIN1 0;
BA_ "GenSigTimeoutTime_MCPB" SG_ 276 MessageCounter_HYBRID_POWERTRAI 0;
BA_ "GenSigTimeoutTime_MCPA" SG_ 276 MessageCounter_HYBRID_POWERTRAI 0;
BA_ "GenSigTimeoutTime_EVCU2" SG_ 276 MessageCounter_HYBRID_POWERTRAI 0;
BA_ "GenSigTimeoutTime_AGSM" SG_ 276 MessageCounter_HYBRID_POWERTRAI 0;
BA_ "SystemSignalLongSymbol" SG_ 276 MessageCounter_HYBRID_POWERTRAI "MessageCounter_HYBRID_POWERTRAIN1";
BA_ "GenSigTimeoutTime_MCPB" SG_ 1033 CRC_HYBRID_POWERTRAIN5 0;
BA_ "GenSigTimeoutTime_MCPA" SG_ 1033 CRC_HYBRID_POWERTRAIN5 0;
BA_ "GenSigTimeoutTime_EVCU2" SG_ 1033 CRC_HYBRID_POWERTRAIN5 0;
BA_ "GenSigTimeoutTime_AGSM" SG_ 1033 CRC_HYBRID_POWERTRAIN5 0;
BA_ "GenSigTimeoutTime_MCPB" SG_ 1033 MessageCounter_HYBRID_POWERTRAI 0;
BA_ "GenSigTimeoutTime_MCPA" SG_ 1033 MessageCounter_HYBRID_POWERTRAI 0;
BA_ "GenSigTimeoutTime_EVCU2" SG_ 1033 MessageCounter_HYBRID_POWERTRAI 0;
BA_ "GenSigTimeoutTime_AGSM" SG_ 1033 MessageCounter_HYBRID_POWERTRAI 0;
BA_ "SystemSignalLongSymbol" SG_ 1033 MessageCounter_HYBRID_POWERTRAI "MessageCounter_HYBRID_POWERTRAIN5";
BA_ "GenSigTimeoutTime_EVCU2" SG_ 267 WU_Timer_Value 0;
BA_ "GenSigTimeoutTime_AGSM" SG_ 267 WU_Timer_Value 0;
BA_ "GenSigTimeoutTime_EVCU2" SG_ 267 PerWakeUp_Diag 0;
BA_ "GenSigTimeoutTime_AGSM" SG_ 267 PerWakeUp_Diag 0;
BA_ "GenSigTimeoutTime_MCPA" SG_ 476 ShiftLeverPositionReq 0;
BA_ "GenSigTimeoutTime_AGSM" SG_ 476 ShiftLeverPositionReq 0;
BA_ "GenSigSendType" SG_ 476 ShiftLeverPositionReq 3;
BA_ "GenSigTimeoutTime_EVCU2" SG_ 258 ABSActive 0;
BA_ "GenSigTimeoutTime_AGSM" SG_ 258 ABSActive 0;
BA_ "GenSigTimeoutTime_EVCU2" SG_ 258 CRC_BRAKE2 0;
BA_ "GenSigTimeoutTime_AGSM" SG_ 258 CRC_BRAKE2 0;
BA_ "GenSigTimeoutTime_EVCU2" SG_ 258 ESCActive 0;
BA_ "GenSigTimeoutTime_AGSM" SG_ 258 ESCActive 0;
BA_ "GenSigTimeoutTime_EVCU2" SG_ 258 LatAcceleration_BSM 0;
BA_ "GenSigTimeoutTime_AGSM" SG_ 258 LatAcceleration_BSM 0;
BA_ "GenSigStartValue" SG_ 258 LatAcceleration_BSM 4095;
BA_ "GenSigTimeoutTime_MCPB" SG_ 476 APCM_Stat 0;
BA_ "GenSigTimeoutTime_MCPA" SG_ 476 APCM_Stat 0;
BA_ "GenSigTimeoutTime_AGSM" SG_ 476 APCM_Stat 0;
BA_ "GenSigTimeoutTime_MCPA" SG_ 1153 CRC_BCM10 0;
BA_ "GenSigTimeoutTime_EVCU2" SG_ 1153 CRC_BCM10 0;
BA_ "GenSigTimeoutTime_AGSM" SG_ 1153 CRC_BCM10 0;
BA_ "GenSigTimeoutTime_MCPA" SG_ 1153 MessageCounter_BCM10 0;
BA_ "GenSigTimeoutTime_EVCU2" SG_ 1153 MessageCounter_BCM10 0;
BA_ "GenSigTimeoutTime_AGSM" SG_ 1153 MessageCounter_BCM10 0;
BA_ "GenSigTimeoutTime_EVCU2" SG_ 1066 ExternalTemperature 0;
BA_ "GenSigTimeoutTime_AGSM" SG_ 1066 ExternalTemperature 0;
BA_ "GenSigTimeoutTime_MCPB" SG_ 476 PRNDdisplayFailSts 0;
BA_ "GenSigTimeoutTime_MCPA" SG_ 476 PRNDdisplayFailSts 0;
BA_ "GenSigTimeoutTime_AGSM" SG_ 476 PRNDdisplayFailSts 0;
BA_ "GenSigTimeoutTime_EVCU2" SG_ 258 LatAccelerationFailSts_BSM 0;
BA_ "GenSigTimeoutTime_AGSM" SG_ 258 LatAccelerationFailSts_BSM 0;
BA_ "GenSigTimeoutTime_EVCU2" SG_ 258 LongAcceleration_BSM 0;
BA_ "GenSigTimeoutTime_AGSM" SG_ 258 LongAcceleration_BSM 0;
BA_ "GenSigStartValue" SG_ 258 LongAcceleration_BSM 4095;
BA_ "GenSigTimeoutTime_EVCU2" SG_ 258 LongAccelerationFailSts_BSM 0;
BA_ "GenSigTimeoutTime_AGSM" SG_ 258 LongAccelerationFailSts_BSM 0;
BA_ "GenSigTimeoutTime_EVCU2" SG_ 258 MessageCounter_BRAKE2 0;
BA_ "GenSigTimeoutTime_AGSM" SG_ 258 MessageCounter_BRAKE2 0;
BA_ "GenSigTimeoutTime_MCPB" SG_ 2564554482 N_PDU 0;
BA_ "GenSigTimeoutTime_MCPA" SG_ 2564554482 N_PDU 0;
BA_ "GenSigTimeoutTime_EVCU2" SG_ 2564554482 N_PDU 0;
BA_ "GenSigTimeoutTime_AGSM" SG_ 2564554482 N_PDU 0;
BA_ "GenSigTimeoutTime_MCPA" SG_ 1155 ESCFailSts 0;
BA_ "GenSigTimeoutTime_EVCU2" SG_ 1155 ESCFailSts 0;
BA_ "GenSigTimeoutTime_AGSM" SG_ 1155 ESCFailSts 0;
BA_ "GenSigSendType" SG_ 1155 ESCFailSts 3;
BA_ "GenSigTimeoutTime_MCPB" SG_ 476 PRNDFailSts 0;
BA_ "GenSigTimeoutTime_MCPA" SG_ 476 PRNDFailSts 0;
BA_ "GenSigTimeoutTime_AGSM" SG_ 476 PRNDFailSts 0;
BA_ "GenSigTimeoutTime_EVCU2" SG_ 1153 CmdIgnSts 0;
BA_ "GenSigTimeoutTime_AGSM" SG_ 1153 CmdIgnSts 0;
BA_ "GenSigSendType" SG_ 1153 CmdIgnSts 3;
BA_ "GenSigTimeoutTime_EVCU2" SG_ 609 EPBSts 0;
BA_ "GenSigTimeoutTime_AGSM" SG_ 609 EPBSts 0;
BA_ "GenSigSendType" SG_ 609 EPBSts 3;
BA_ "GenSigTimeoutTime_MCPA" SG_ 1155 ABSFailSts 0;
BA_ "GenSigTimeoutTime_EVCU2" SG_ 1155 ABSFailSts 0;
BA_ "GenSigTimeoutTime_AGSM" SG_ 1155 ABSFailSts 0;
BA_ "GenSigSendType" SG_ 1155 ABSFailSts 3;
VAL_ 1626 IMPACTConfirm 0 "Actuate" 1 "Do_Not_Actuate";
VAL_ 1626 IMPACTCommand 0 "Do_Not_Actuate" 1 "Actuate";
VAL_ 1155 ESCFailSts 0 "Fail_Not_Present" 1 "Fail_Present";
VAL_ 1155 ABSFailSts 0 "Fail_Not_Present" 1 "Fail_Present";
VAL_ 609 EPBSts 0 "Released" 1 "Applied" 2 "DynamicBrkESC" 3 "DynamicBrkEPB" 4 "Emergency_Braking" 5 "Applying" 6 "Maintenance_Mode" 7 "Assembly_Check" 8 "Inspection_Mode" 9 "Re_Clamping" 10 "Adjuste_Mode" 11 "Releasing" 12 "Fault_EPB_Released" 13 "Fault_EPB_Applied" 14 "Fault_Present" 15 "SNA";
VAL_ 1153 CmdIgnSts 0 "Initialization" 1 "IGN_LK" 3 "ACC" 4 "RUN" 5 "START" 7 "SNA";
VAL_ 476 PRNDFailSts 0 "Fail_Not_Present" 1 "Fail_Present";
VAL_ 476 PRNDdisplayFailSts 0 "Fail_not_present" 1 "Fail_present";
VAL_ 1066 ExternalTemperature 511 "SNA";
VAL_ 258 LongAccelerationFailSts_BSM 0 "Fail_Not_Present" 1 "Fail_Present";
VAL_ 258 LongAcceleration_BSM 4095 "SNA";
VAL_ 258 LatAccelerationFailSts_BSM 0 "Fail_Not_Present" 1 "Fail_Present";
VAL_ 258 LatAcceleration_BSM 4095 "SNA";
VAL_ 258 ESCActive 0 "Not_active" 1 "Active";
VAL_ 258 ABSActive 0 "Not_active" 1 "Active";
VAL_ 476 APCM_Stat 0 "OFF" 1 "ON" 2 "PENDING" 3 "SNA";
VAL_ 156 GPS_UTC_Second 65535 "SNA";
VAL_ 156 GPS_UTC_Minute 255 "SNA";
VAL_ 156 GPS_UTC_Hour 255 "SNA";
VAL_ 156 GPS_Date_Year 65535 "SNA";
VAL_ 156 GPS_Date_Month 255 "SNA";
VAL_ 156 GPS_Date_Day 255 "SNA";
VAL_ 2654486617 CBV_bit6_PartialNtwInfBit 0 "NM PDU contains no Partial Network request information" 1 "NM PDU contains Partial Network request information";
VAL_ 2654486616 CBV_bit6_PartialNtwInfBit 0 "NM PDU contains no Partial Network request information" 1 "NM PDU contains Partial Network request information";
VAL_ 2654486592 CBV_bit4_ActiveWakeupBit 0 "PassiveWakeup" 1 "ActiveWakeup";
VAL_ 2654486616 CBV_bit4_ActiveWakeupBit 0 "PassiveWakeup" 1 "ActiveWakeup";
VAL_ 2654486617 CBV_bit4_ActiveWakeupBit 0 "PassiveWakeup" 1 "ActiveWakeup";
VAL_ 2654486616 CBV_bit3_NMCoordinatorBit 0 "Start of synchronized shutdown is not requested by main coordinator" 1 "Start of synchronized shutdown is requested by main coordinator";
VAL_ 2654486617 CBV_bit3_NMCoordinatorBit 0 "Start of synchronized shutdown is not requested by main coordinator" 1 "Start of synchronized shutdown is requested by main coordinator";
VAL_ 2654486617 CBV_bit0_RepeatMessageRequestBit 0 "Repeat Message State not requested" 1 "Repeat Message State requested";
VAL_ 2654486616 CBV_bit0_RepeatMessageRequestBit 0 "Repeat Message State not requested" 1 "Repeat Message State requested";
VAL_ 105 T7_CoolantTempVldty 0 "Valid" 1 "Not_Valid";
VAL_ 263 GearEngagedForDisplay_PT 0 "Initialize" 1 "Gear_1st" 2 "Gear_2nd" 3 "Gear_3rd" 4 "Gear_4th" 5 "Gear_5th" 6 "Gear_6th" 7 "Gear_7th" 8 "Gear_8th" 9 "Gear_9th" 12 "Park" 13 "Neutral" 14 "Reverse" 15 "Drive" 16 "Low" 17 "Manual" 18 "Sport_Mode" 31 "SNA";
VAL_ 263 GearEngaged_PT 0 "Neutral" 1 "ForwardGear_1" 2 "ForwardGear_2" 3 "ForwardGear_3" 4 "ForwardGear_4" 5 "ForwardGear_5" 6 "ForwardGear_6" 7 "ForwardGear_7" 8 "ForwardGear_8" 9 "ForwardGear_9" 13 "Parking" 14 "ReverseGear" 15 "SNA";
VAL_ 496 Plock_fdbk_sts 0 "Init" 1 "Engaging" 2 "Engaged" 3 "Disengaging" 4 "Disengaged" 5 "Fault" 7 "SNA";
VAL_ 263 TransmissionFailSts_PT 0 "Fail_not_present" 1 "Fail_present";
VAL_ 263 ShiftLeverPosition_PT 0 "No_Selection_Active_Or_Available" 1 "Park" 2 "Reverse" 3 "Neutral" 4 "Drive" 5 "Low" 6 "TIP_Autostick" 7 "Plus" 8 "Minus" 9 "Sport" 15 "SNA";
VAL_ 263 GearIndicationSts_PT 0 "Normal" 1 "Blinking";
VAL_ 263 APCM_Rq_PT 0 "OFF" 1 "ON" 2 "Pending" 3 "SNA";
VAL_ 1811 Real_Time_Validity 0 "Valid" 1 "Not_Valid";
VAL_ 1811 Real_Time_Clock 4294967295 "SNA";
VAL_ 476 ShiftLeverPositionReq 0 "No_Selection_Active_Or_Available" 1 "P" 2 "R" 3 "N" 4 "D" 5 "L" 6 "TIP_Autostick" 7 "Plus" 8 "Minus" 9 "Sport" 10 "Not_Used" 11 "Not_Used" 12 "Not_Used" 13 "Not_Used" 14 "Not_Used" 15 "SNA";
VAL_ 1065 MCPB_DTC_Stat2 0 "Not_Supported" 1 "Critically_disabled" 2 "No_status_to_report" 3 "Diagnostic_passed" 4 "Diagnostic_failed" 5 "Reset_DTC_status" 7 "SNA";
VAL_ 1065 MCPB_DTC_Stat1 0 "Not_Supported" 1 "Critically_disabled" 2 "No_status_to_report" 3 "Diagnostic_passed" 4 "Diagnostic_failed" 5 "Reset_DTC_status" 7 "SNA";
VAL_ 1065 MCPB_DTC_Idx2 31 "SNA";
VAL_ 1065 MCPB_DTC_Idx1 31 "SNA";
VAL_ 1065 MCPB_CalChar 255 "SNA";
VAL_ 1065 MCPB_Cal_ID_Idx 63 "SNA";
VAL_ 1057 MCPA_DTC_Stat2 0 "Not_Supported" 1 "Critically_disabled" 2 "No_status_to_report" 3 "Diagnostic_passed" 4 "Diagnostic_failed" 5 "Reset_DTC_status" 7 "SNA";
VAL_ 1057 MCPA_DTC_Stat1 0 "Not_Supported" 1 "Critically_disabled" 2 "No_status_to_report" 3 "Diagnostic_passed" 4 "Diagnostic_failed" 5 "Reset_DTC_status" 7 "SNA";
VAL_ 1057 MCPA_DTC_Idx2 31 "SNA";
VAL_ 1057 MCPA_DTC_Idx1 31 "SNA";
VAL_ 1057 MCPA_CalChar 255 "SNA";
VAL_ 1057 MCPA_Cal_ID_Idx 63 "SNA";
VAL_ 1032 EOPB_OIL_TEMP 255 "SNA";
VAL_ 1032 EOPB_OIL_FlwRate 255 "SNA";
VAL_ 1032 EOPA_OIL_TEMP 255 "SNA";
VAL_ 1032 EOPA_OIL_FlwRate 255 "SNA";
VAL_ 504 MCPB_DerateReason_P 0 "Reason1" 1 "Reason2" 2 "Reason3" 3 "Reason4" 4 "Reason5" 5 "Reason6" 6 "Reason7" 7 "Reason8" 8 "Reason9" 9 "Reason10" 10 "Reason11" 11 "Reason12" 12 "Reason13" 13 "Reason14" 14 "Reason15" 15 "Reason16";
VAL_ 504 MCPB_DC_Voltage_P 1023 "SNA";
VAL_ 504 MCPB_DC_Volt_V_P 0 "Valid" 1 "Invalid";
VAL_ 504 MCPB_DC_Current_V_P 0 "Valid" 1 "Invalid";
VAL_ 504 MCPB_CoolantTemp_P 2047 "SNA";
VAL_ 294 PlockFailSts_P 0 "Fault_Not_Present" 1 "Derating" 2 "Retrying" 3 "Non recoverable critical fault" 7 "SNA";
VAL_ 294 Plock_PosSensor_P 0 "Init" 1 "Unknown" 2 "Engaged" 3 "Between Engaged and Disengaged" 4 "Tooth to Tooth" 5 "Disengaged" 7 "SNA";
VAL_ 294 Plock_MotorPosSts_P 0 "Init" 1 "Unknown" 2 "Engaged Endstop" 3 "Engaged" 4 "Between Engaged and Disengaged" 5 "Disengaged" 6 "Disengaged Endstop" 7 "SNA";
VAL_ 294 Plock_fdbk_sts_P 0 "Init" 1 "Engaging" 2 "Engaged" 3 "Disengaging" 4 "Disengaged" 5 "Fault" 7 "SNA";
VAL_ 294 MPR_PosSensor_P 0 "Init" 1 "Unknown" 2 "Engaged" 3 "Disengaged" 7 "SNA";
VAL_ 294 MCPB_Torque_Achieved_V_P 0 "Valid" 1 "Invalid";
VAL_ 294 MCPB_Torque_Achieved_P 16383 "SNA";
VAL_ 294 MCPB_TorqAchieved_AEMD_V_P 0 "Valid" 1 "Invalid";
VAL_ 294 MCPB_TorqAchieved_AEMD_P 16383 "SNA";
VAL_ 294 MCPB_SPT_Stat_P 0 "Undetermined " 1 "Passed" 2 "Failed";
VAL_ 294 MCPB_RPM_V_P 0 "Valid" 1 "Invalid";
VAL_ 294 MCPB_RPM_P 65535 "SNA";
VAL_ 294 MCPB_MtrMinCpbltyTrq_P 16383 "SNA";
VAL_ 294 MCPB_MtrMaxCpbltyTrq_P 16383 "SNA";
VAL_ 294 MCPB_MtrIndex_P 31 "SNA";
VAL_ 294 MCPB_MinTorq_P 16383 "SNA";
VAL_ 294 MCPB_MaxTorq_P 16383 "SNA";
VAL_ 294 MCPB_Invrtr_State_P 0 "NORMAL_POWER_STAGE_OFF " 1 "NORMAL_POWER_STAGE_ON " 2 "NORMAL_POWER_STAGE_OVERRIDE" 3 "ACTIVE_DISCHARGE " 4 "INVERTER_FAULTED " 5 "NORMAL_POWER_STAGE_OFF_HV_RQD" 6 "NORMAL_VC_PRIMING" 7 "NORMAL_VC_ON";
VAL_ 294 MCPB_InterlockSts_P 0 "Not_Performed" 1 "OK" 2 "Fail" 3 "Invalid";
VAL_ 294 MCPB_HV_CnctrOpn_Req_P 0 "False" 1 "True";
VAL_ 294 MCPB_Dschrge_Status_P 0 "AD_INDETERMINATE" 1 "AD_INPROGRESS" 2 "AD_COMPLETE" 3 "AD_FAILED";
VAL_ 294 MCPB_DeratingFactor_P 63 "SNA";
VAL_ 294 MCPB_CpbltySpdDivVolt_P 65535 "SNA";
VAL_ 294 MCPB_AccelRawV_P 0 "Valid" 1 "Invalid";
VAL_ 294 MCPB_6SO_Status_P 0 "ThreePS" 1 "SixSO" 2 "Switching" 3 "SNA";
VAL_ 294 MCPB_3PS_Pos_P 0 "False" 1 "True";
VAL_ 503 MCPA_DerateReason_P 0 "Reason1" 1 "Reason2" 2 "Reason3" 3 "Reason4" 4 "Reason5" 5 "Reason6" 6 "Reason7" 7 "Reason8" 8 "Reason9" 9 "Reason10" 10 "Reason11" 11 "Reason12" 12 "Reason13" 13 "Reason14" 14 "Reason15" 15 "Reason16";
VAL_ 503 MCPA_DC_Voltage_P 1023 "SNA";
VAL_ 503 MCPA_DC_Volt_V_P 0 "Valid" 1 "Invalid";
VAL_ 503 MCPA_DC_Current_V_P 0 "Valid" 1 "Invalid";
VAL_ 503 MCPA_CoolantTemp_P 2047 "SNA";
VAL_ 293 MCPA_Torque_Achieved_V_P 0 "Valid" 1 "Invalid";
VAL_ 293 MCPA_Torque_Achieved_P 16383 "SNA";
VAL_ 293 MCPA_TorqAchieved_AEMD_V_P 0 "Valid" 1 "Invalid";
VAL_ 293 MCPA_TorqAchieved_AEMD_P 16383 "SNA";
VAL_ 293 MCPA_SPT_Stat_P 0 "Undetermined" 1 "Passed" 2 "Failed";
VAL_ 293 MCPA_RPM_V_P 0 "Valid" 1 "Invalid";
VAL_ 293 MCPA_RPM_P 65535 "SNA";
VAL_ 293 MCPA_MtrMinCpbltyTrq_P 16383 "SNA";
VAL_ 293 MCPA_MtrMaxCpbltyTrq_P 16383 "SNA";
VAL_ 293 MCPA_MtrIndex_P 31 "SNA";
VAL_ 293 MCPA_MinTorq_P 16383 "SNA";
VAL_ 293 MCPA_MaxTorq_P 16383 "SNA";
VAL_ 293 MCPA_Invrtr_State_P 0 "NORMAL_POWER_STAGE_OFF" 1 "NORMAL_POWER_STAGE_ON" 2 "NORMAL_POWER_STAGE_OVERRIDE" 3 "ACTIVE_DISCHARGE" 4 "INVERTER_FAULTED" 5 "NORMAL_POWER_STAGE_OFF_HV_RQD" 6 "NORMAL_VC_PRIMING" 7 "NORMAL_VC_ON";
VAL_ 293 MCPA_InterlockSts_P 0 "Not_Performed" 1 "OK" 2 "Fail" 3 "Invalid";
VAL_ 293 MCPA_HV_CnctrOpn_Req_P 0 "False" 1 "True";
VAL_ 293 MCPA_Dschrge_Status_P 0 "AD_INDETERMINATE" 1 "AD_INPROGRESS" 2 "AD_COMPLETE" 3 "AD_FAILED";
VAL_ 293 MCPA_DeratingFactor_P 63 "SNA";
VAL_ 293 MCPA_CpbltySpdDivVolt_P 65535 "SNA";
VAL_ 293 MCPA_AccelRawV_P 0 "Valid" 1 "Invalid";
VAL_ 293 MCPA_6SO_Status_P 0 "ThreePS" 1 "SixSO" 2 "Switching" 3 "SNA";
VAL_ 293 MCPA_3PS_Pos_P 0 "False" 1 "True";
VAL_ 297 Pwr_Electr_Loop_FlwRate_MCPB_P 255 "SNA";
VAL_ 297 Pwr_Electr_Loop_FlwRate_MCPA_P 255 "SNA";
VAL_ 297 EVCU_MotorB_Speed 65535 "SNA";
VAL_ 297 EVCU_MotorA_Speed 65535 "SNA";
VAL_ 296 VehicleSpeedVSOSig_P 8191 "SNA";
VAL_ 296 TorqueCommand_MCPB_P 16383 "SNA";
VAL_ 296 TorqueCommand_MCPA_P 16383 "SNA";
VAL_ 296 ShiftLeverPosition_P 0 "No_Selection_Active_Or_Available" 1 "Park" 2 "Reverse" 3 "Neutral" 4 "Drive" 5 "Low" 6 "TIP_Autostick" 7 "Plus" 8 "Minus" 9 "Sport" 15 "SNA";
VAL_ 296 ParkCmd_PT_P 0 "No_Request" 1 "Disengage" 2 "Engage" 3 "SNA";
VAL_ 296 Mtr_6SO_Request_MCPB_P 0 "False" 1 "True";
VAL_ 296 Mtr_6SO_Request_MCPA_P 0 "False" 1 "True";
VAL_ 296 ModeCommand_MCPB_P 0 "Inverter_Disabled" 1 "Torque_Control" 2 "Speed_Control" 3 "Active_Discharge" 4 "Disable_Immediate" 5 "Voltage_Control" 6 "0x6 Rapid_Shutdown" 7 "Shutdown_Initiated" 8 "ROL_Routine" 9 "Active_Short_Circuit" 15 "SNA";
VAL_ 296 ModeCommand_MCPA_P 0 "Inverter_Disabled" 1 "Torque_Control" 2 "Speed_Control" 3 "Active_Discharge" 4 "Disable_Immediate" 5 "Voltage_Control" 6 "0x6 Rapid_Shutdown" 7 "Shutdown_Initiated" 8 "ROL_Routine" 9 "Active_Short_Circuit" 15 "SNA";
VAL_ 296 CmdIgnSts_P 0 "Initialization" 1 "IGN_LK" 3 "ACC" 4 "RUN" 5 "START" 7 "SNA";
VAL_ 296 BPCM_HV_TractionBusVoltage_P 2047 "SNA";
VAL_ 296 BPCM_HV_Trac_Main_Contac_Sts_P 0 "Open" 1 "Closed" 3 "Error_Stuck_Open" 4 "Error_Stuck_Closed" 7 "SNA";
VAL_ 296 AEMD_MinOffset_MCPB_P 16383 "SNA";
VAL_ 296 AEMD_MinOffset_MCPA_P 16383 "SNA";
VAL_ 296 AEMD_MaxOffset_MCPB_P 16383 "SNA";
VAL_ 296 AEMD_MaxOffset_MCPA_P 16383 "SNA";
VAL_ 294 MCPB_AccelRaw_P 65535 "SNA";
VAL_ 293 MCPA_AccelRaw_P 65535 "SNA";
VAL_ 296 AEMD_Sclr_Gn_MCPB_P 511 "SNA";
VAL_ 296 AEMD_Sclr_Gn_MCPA_P 511 "SNA";
VAL_ 504 MCPB_Inverter_Temp_P 255 "SNA";
VAL_ 504 MCPB_PIM_DC_Side_Busbar_Temp_P 255 "SNA";
VAL_ 504 MCPB_Rotor_Temperature_P 255 "SNA";
VAL_ 504 MCPB_Service_Lamp_Request_P 0 "False" 1 "True";
VAL_ 504 CLrDiagInfo_MCPB_P 0 "False" 1 "True";
VAL_ 504 MCPB_Control_Board_Temperature_P 255 "SNA";
VAL_ 294 MCPB_AC_Isolation_Status_P 0 "Not_Performed" 1 "Invalid" 2 "Fail" 3 "Pass";
VAL_ 294 MCPB_Temp_P 255 "SNA";
VAL_ 503 MCPA_Inverter_Temp_P 255 "SNA";
VAL_ 503 MCPA_PIM_DC_Side_Busbar_Temp_P 255 "SNA";
VAL_ 503 MCPA_Rotor_Temperature_P 255 "SNA";
VAL_ 503 MCPA_Service_Lamp_Request_P 0 "False" 1 "True";
VAL_ 503 CLrDiagInfo_MCPA_P 0 "False" 1 "True";
VAL_ 503 MCPA_Control_Board_Temperature_P 255 "SNA";
VAL_ 293 MCPA_Temp_P 255 "SNA";
VAL_ 293 MCPA_AC_Isolation_Status_P 0 "Not_Performed" 1 "Invalid" 2 "Fail" 3 "Pass";

SIG_GROUP_ 1033 HYBRID_POWERTRAIN5_Pkt 1 : MessageCounter_HYBRID_POWERTRAI CRC_HYBRID_POWERTRAIN5;
SIG_GROUP_ 276 HYBRID_POWERTRAIN1_Pkt 1 : MessageCounter_HYBRID_POWERTRAI CRC_HYBRID_POWERTRAIN1;
SIG_GROUP_ 476 AGSM_FD_2_Pkt 1 : CRC_AGSM2 MessageCounter_AGSM2 PRNDFailSts PRNDdisplayFailSts APCM_Stat ShiftLeverPositionReq;
SIG_GROUP_ 496 PARK_DATA_Pkt 1 : MessageCounter_PARK_DATA CRC_PARK_DATA Plock_fdbk_sts;
SIG_GROUP_ 263 PT_SYSTEM_FD_1_Pkt 1 : GearEngagedForDisplay_PT GearEngaged_PT TransmissionFailSts_PT ShiftLeverPosition_PT MessageCounter_PT_SYSTEM_FD_1 GearIndicationSts_PT CRC_PT_SYSTEM_FD_1 APCM_Rq_PT;
SIG_GROUP_ 216 PT_ENERGY_FD_1_Pkt 1 : CRC_PT_ENERGY_FD_1 MC_PT_ENERGY_FD_1 BatteryVoltage_Raw_PT;
SIG_GROUP_ 297 INVTARGET_PROPULSION2_Pkt 1 : UDCMin_Unlim_MCPB_P UDCMin_Unlim_MCPA_P UDCMax_Unlim_MCPB_P UDCMax_Unlim_MCPA_P TqGrdtLim_MCPB_P TqGrdtLim_MCPA_P SpdGrdtLim_MCPB_P SpdGrdtLim_MCPA_P Pwr_Electr_Loop_FlwRate_MCPB_P Pwr_Electr_Loop_FlwRate_MCPA_P MC_INVTARGET_PROPULSION2 EVCU_MotorB_Speed EVCU_MotorA_Speed CRC_INVTARGET_PROPULSION2;
SIG_GROUP_ 296 INVTARGET_PROPULSION1_Pkt 1 : VehicleSpeedVSOSig_P TorqueCommand_MCPB_P TorqueCommand_MCPA_P TargetMotorRPM_MCPB_P TargetMotorRPM_MCPA_P ShiftLeverPosition_P ParkCmd_PT_P Mtr_6SO_Request_MCPB_P Mtr_6SO_Request_MCPA_P ModeCommand_MCPB_P ModeCommand_MCPA_P MC_INVTARGET_PROPULSION1 CRC_INVTARGET_PROPULSION1 CmdIgnSts_P BPCM_HV_TractionBusVoltage_P BPCM_HV_Trac_Main_Contac_Sts_P AEMD_MinOffset_MCPB_P AEMD_MinOffset_MCPA_P AEMD_MaxOffset_MCPB_P AEMD_MaxOffset_MCPA_P AEMD_Cutoff_FreqLow_MCPB_P AEMD_Cutoff_FreqLow_MCPA_P AEMD_Cutoff_FreqHigh_MCPB_P AEMD_Cutoff_FreqHigh_MCPA_P AEMD_Sclr_Gn_MCPB_P AEMD_Sclr_Gn_MCPA_P;
SIG_GROUP_ 294 MCPB_PROPULSION_Pkt 1 : PlockFailSts_P Plock_PosSensor_P Plock_MotorPosSts_P Plock_fdbk_sts_P MPR_PosSensor_P MCPB_Torque_Achieved_V_P MCPB_Torque_Achieved_P MCPB_TorqAchieved_AEMD_V_P MCPB_TorqAchieved_AEMD_P MCPB_SPT_Stat_P MCPB_Spd_Lim_P MCPB_RPM_V_P MCPB_RPM_P MCPB_MtrMinCpbltyTrq_P MCPB_MtrMaxCpbltyTrq_P MCPB_MtrIndex_P MCPB_MinTorq_P MCPB_MaxTorq_P MCPB_Invrtr_State_P MCPB_InterlockSts_P MCPB_HV_CnctrOpn_Req_P MCPB_Dschrge_Status_P MCPB_DeratingFactor_P MCPB_CpbltySpdDivVolt_P MCPB_AccelRawV_P MCPB_6SO_Status_P MCPB_3PS_Pos_P MCPB_AccelRaw_P MC_MCPB_PROPULSION CRC_MCPB_PROPULSION MCPB_AC_Isolation_Status_P MCPB_Temp_P;
SIG_GROUP_ 293 MCPA_PROPULSION_Pkt 1 : MCPA_Torque_Achieved_V_P MCPA_Torque_Achieved_P MCPA_TorqAchieved_AEMD_V_P MCPA_TorqAchieved_AEMD_P MCPA_SPT_Stat_P MCPA_Spd_Lim_P MCPA_RPM_V_P MCPA_RPM_P MCPA_MtrMinCpbltyTrq_P MCPA_MtrMaxCpbltyTrq_P MCPA_MtrIndex_P MCPA_MinTorq_P MCPA_MaxTorq_P MCPA_Invrtr_State_P MCPA_InterlockSts_P MCPA_HV_CnctrOpn_Req_P MCPA_Dschrge_Status_P MCPA_DeratingFactor_P MCPA_CpbltySpdDivVolt_P MCPA_AccelRawV_P MCPA_6SO_Status_P MCPA_3PS_Pos_P MCPA_AccelRaw_P MC_MCPA_PROPULSION CRC_MCPA_PROPULSION MCPA_Temp_P MCPA_AC_Isolation_Status_P;
